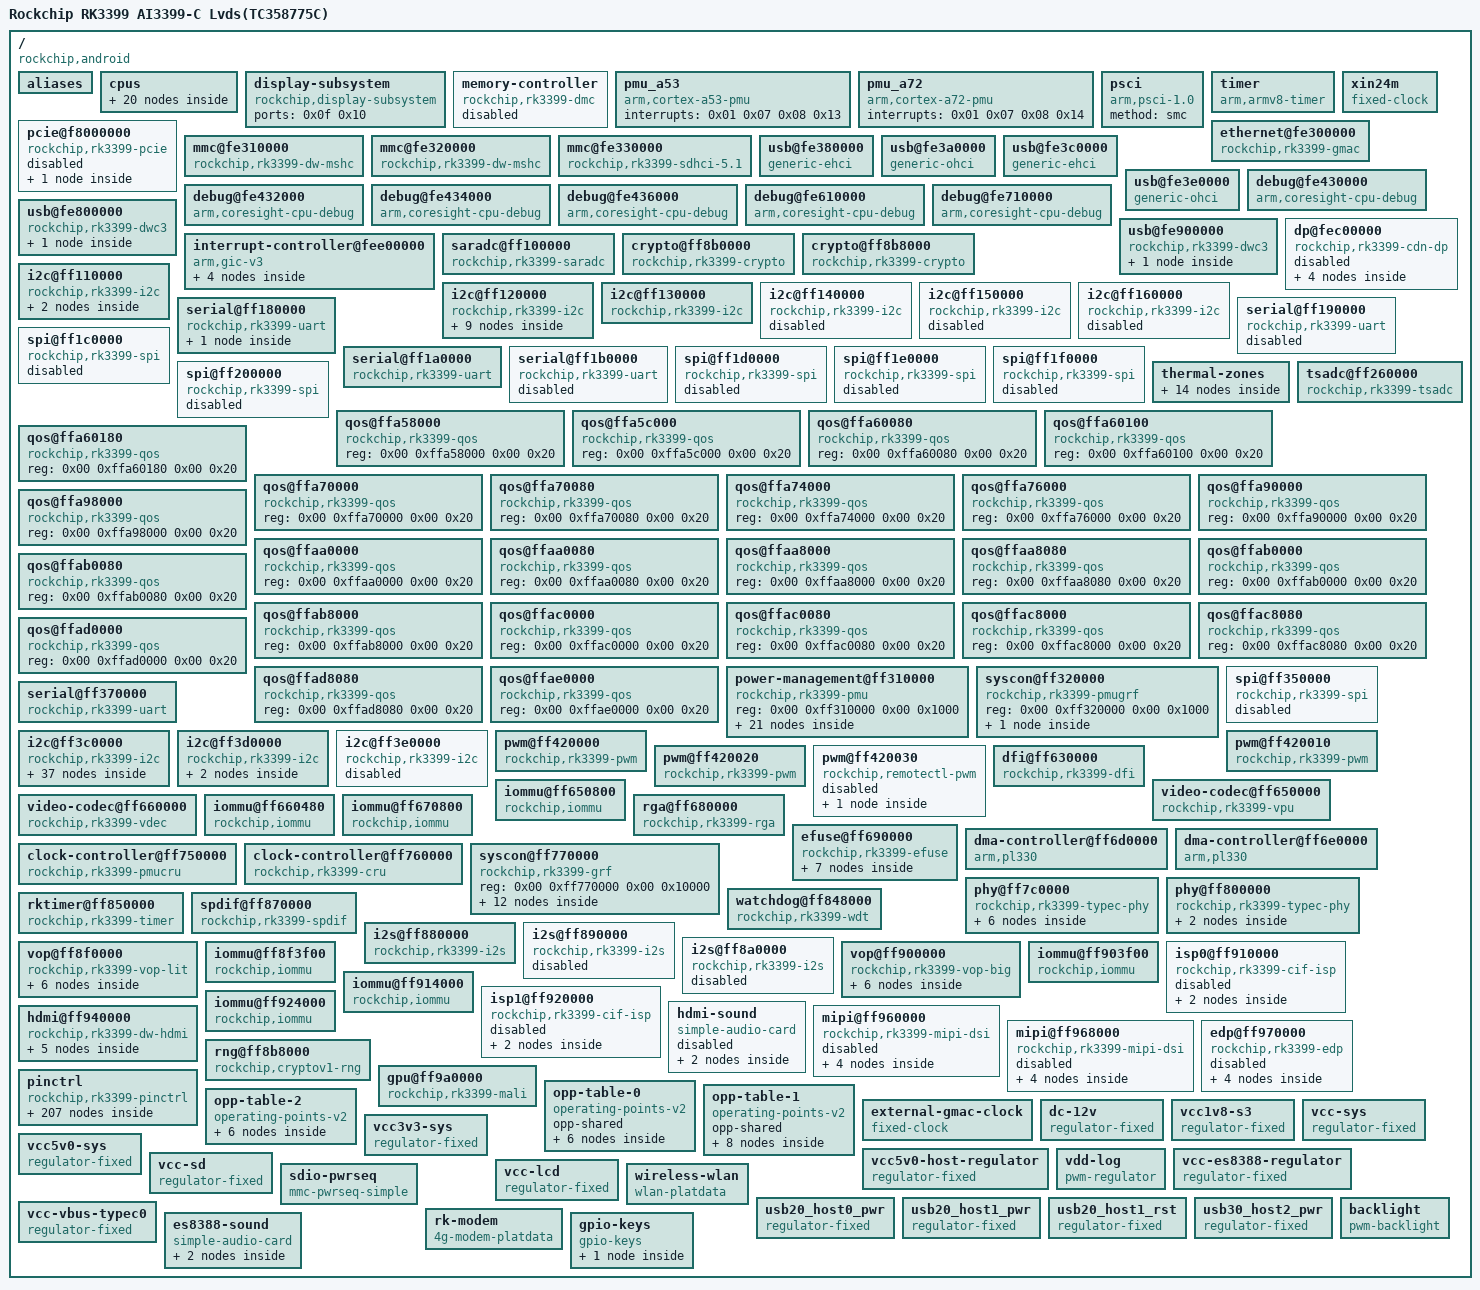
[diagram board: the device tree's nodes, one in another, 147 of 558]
/dts-v1/;

/ {
	compatible = "rockchip,android\0rockchip,rk3399-ai3399c-lvds\0rockchip,rk3399";
	interrupt-parent = <0x01>;
	#address-cells = <0x02>;
	#size-cells = <0x02>;
	serial-number = "STVQPGOW8K";
	model = "Rockchip RK3399 AI3399-C Lvds(TC358775C)";
	signway,hwid = "01.02.03.04.05.06.07.08";

	aliases {
		ethernet0 = "/ethernet@fe300000";
		i2c0 = "/i2c@ff3c0000";
		i2c1 = "/i2c@ff110000";
		i2c2 = "/i2c@ff120000";
		i2c3 = "/i2c@ff130000";
		i2c4 = "/i2c@ff3d0000";
		i2c5 = "/i2c@ff140000";
		i2c6 = "/i2c@ff150000";
		i2c7 = "/i2c@ff160000";
		i2c8 = "/i2c@ff3e0000";
		serial0 = "/serial@ff180000";
		serial1 = "/serial@ff190000";
		serial2 = "/serial@ff1a0000";
		serial3 = "/serial@ff1b0000";
		serial4 = "/serial@ff370000";
		mmc0 = "/mmc@fe330000";
	};

	cpus {
		#address-cells = <0x02>;
		#size-cells = <0x00>;

		cpu-map {

			cluster0 {

				core0 {
					cpu = <0x02>;
				};

				core1 {
					cpu = <0x03>;
				};

				core2 {
					cpu = <0x04>;
				};

				core3 {
					cpu = <0x05>;
				};
			};

			cluster1 {

				core0 {
					cpu = <0x06>;
				};

				core1 {
					cpu = <0x07>;
				};
			};
		};

		cpu@0 {
			device_type = "cpu";
			compatible = "arm,cortex-a53";
			reg = <0x00 0x00>;
			enable-method = "psci";
			capacity-dmips-mhz = <0x1e5>;
			clocks = <0x08 0x08>;
			#cooling-cells = <0x02>;
			dynamic-power-coefficient = <0x64>;
			cpu-idle-states = <0x09 0x0a>;
			operating-points-v2 = <0x0b>;
			cpu-supply = <0x0c>;
			phandle = <0x02>;
		};

		cpu@1 {
			device_type = "cpu";
			compatible = "arm,cortex-a53";
			reg = <0x00 0x01>;
			enable-method = "psci";
			capacity-dmips-mhz = <0x1e5>;
			clocks = <0x08 0x08>;
			#cooling-cells = <0x02>;
			dynamic-power-coefficient = <0x64>;
			cpu-idle-states = <0x09 0x0a>;
			operating-points-v2 = <0x0b>;
			cpu-supply = <0x0c>;
			phandle = <0x03>;
		};

		cpu@2 {
			device_type = "cpu";
			compatible = "arm,cortex-a53";
			reg = <0x00 0x02>;
			enable-method = "psci";
			capacity-dmips-mhz = <0x1e5>;
			clocks = <0x08 0x08>;
			#cooling-cells = <0x02>;
			dynamic-power-coefficient = <0x64>;
			cpu-idle-states = <0x09 0x0a>;
			operating-points-v2 = <0x0b>;
			cpu-supply = <0x0c>;
			phandle = <0x04>;
		};

		cpu@3 {
			device_type = "cpu";
			compatible = "arm,cortex-a53";
			reg = <0x00 0x03>;
			enable-method = "psci";
			capacity-dmips-mhz = <0x1e5>;
			clocks = <0x08 0x08>;
			#cooling-cells = <0x02>;
			dynamic-power-coefficient = <0x64>;
			cpu-idle-states = <0x09 0x0a>;
			operating-points-v2 = <0x0b>;
			cpu-supply = <0x0c>;
			phandle = <0x05>;
		};

		cpu@100 {
			device_type = "cpu";
			compatible = "arm,cortex-a72";
			reg = <0x00 0x100>;
			enable-method = "psci";
			capacity-dmips-mhz = <0x400>;
			clocks = <0x08 0x09>;
			#cooling-cells = <0x02>;
			dynamic-power-coefficient = <0x1b4>;
			cpu-idle-states = <0x09 0x0a>;
			operating-points-v2 = <0x0d>;
			cpu-supply = <0x0e>;
			phandle = <0x06>;

			thermal-idle {
				#cooling-cells = <0x02>;
				duration-us = <0x2710>;
				exit-latency-us = <0x1f4>;
			};
		};

		cpu@101 {
			device_type = "cpu";
			compatible = "arm,cortex-a72";
			reg = <0x00 0x101>;
			enable-method = "psci";
			capacity-dmips-mhz = <0x400>;
			clocks = <0x08 0x09>;
			#cooling-cells = <0x02>;
			dynamic-power-coefficient = <0x1b4>;
			cpu-idle-states = <0x09 0x0a>;
			operating-points-v2 = <0x0d>;
			cpu-supply = <0x0e>;
			phandle = <0x07>;

			thermal-idle {
				#cooling-cells = <0x02>;
				duration-us = <0x2710>;
				exit-latency-us = <0x1f4>;
			};
		};

		idle-states {
			entry-method = "psci";

			cpu-sleep {
				compatible = "arm,idle-state";
				local-timer-stop;
				arm,psci-suspend-param = <0x10000>;
				entry-latency-us = <0x78>;
				exit-latency-us = <0xfa>;
				min-residency-us = <0x384>;
				phandle = <0x09>;
			};

			cluster-sleep {
				compatible = "arm,idle-state";
				local-timer-stop;
				arm,psci-suspend-param = <0x1010000>;
				entry-latency-us = <0x190>;
				exit-latency-us = <0x1f4>;
				min-residency-us = <0x7d0>;
				phandle = <0x0a>;
			};
		};
	};

	display-subsystem {
		compatible = "rockchip,display-subsystem";
		ports = <0x0f 0x10>;
	};

	memory-controller {
		compatible = "rockchip,rk3399-dmc";
		rockchip,pmu = <0x11>;
		devfreq-events = <0x12>;
		clocks = <0x08 0xa8>;
		clock-names = "dmc_clk";
		status = "disabled";
		phandle = <0xdc>;
	};

	pmu_a53 {
		compatible = "arm,cortex-a53-pmu";
		interrupts = <0x01 0x07 0x08 0x13>;
	};

	pmu_a72 {
		compatible = "arm,cortex-a72-pmu";
		interrupts = <0x01 0x07 0x08 0x14>;
	};

	psci {
		compatible = "arm,psci-1.0";
		method = "smc";
	};

	timer {
		compatible = "arm,armv8-timer";
		interrupts = <0x01 0x0d 0x08 0x00 0x01 0x0e 0x08 0x00 0x01 0x0b 0x08 0x00 0x01 0x0a 0x08 0x00>;
		arm,no-tick-in-suspend;
	};

	xin24m {
		compatible = "fixed-clock";
		clock-frequency = <0x16e3600>;
		clock-output-names = "xin24m";
		#clock-cells = <0x00>;
		phandle = <0x9b>;
	};

	pcie@f8000000 {
		compatible = "rockchip,rk3399-pcie";
		reg = <0x00 0xf8000000 0x00 0x2000000 0x00 0xfd000000 0x00 0x1000000>;
		reg-names = "axi-base\0apb-base";
		device_type = "pci";
		#address-cells = <0x03>;
		#size-cells = <0x02>;
		#interrupt-cells = <0x01>;
		aspm-no-l0s;
		bus-range = <0x00 0x1f>;
		clocks = <0x08 0xc5 0x08 0xc4 0x08 0x147 0x08 0xa0>;
		clock-names = "aclk\0aclk-perf\0hclk\0pm";
		interrupts = <0x00 0x31 0x04 0x00 0x00 0x32 0x04 0x00 0x00 0x33 0x04 0x00>;
		interrupt-names = "sys\0legacy\0client";
		interrupt-map-mask = <0x00 0x00 0x00 0x07>;
		interrupt-map = <0x00 0x00 0x00 0x01 0x15 0x00 0x00 0x00 0x00 0x02 0x15 0x01 0x00 0x00 0x00 0x03 0x15 0x02 0x00 0x00 0x00 0x04 0x15 0x03>;
		max-link-speed = <0x01>;
		msi-map = <0x00 0x16 0x00 0x1000>;
		phys = <0x17 0x00 0x17 0x01 0x17 0x02 0x17 0x03>;
		phy-names = "pcie-phy-0\0pcie-phy-1\0pcie-phy-2\0pcie-phy-3";
		ranges = <0x82000000 0x00 0xfa000000 0x00 0xfa000000 0x00 0x1e00000 0x81000000 0x00 0xfbe00000 0x00 0xfbe00000 0x00 0x100000>;
		resets = <0x08 0x82 0x08 0x83 0x08 0x84 0x08 0x85 0x08 0x86 0x08 0x81 0x08 0x80>;
		reset-names = "core\0mgmt\0mgmt-sticky\0pipe\0pm\0pclk\0aclk";
		status = "disabled";
		phandle = <0xdd>;

		interrupt-controller {
			interrupt-controller;
			#address-cells = <0x00>;
			#interrupt-cells = <0x01>;
			phandle = <0x15>;
		};
	};

	ethernet@fe300000 {
		compatible = "rockchip,rk3399-gmac";
		reg = <0x00 0xfe300000 0x00 0x10000>;
		interrupts = <0x00 0x0c 0x04 0x00>;
		interrupt-names = "macirq";
		clocks = <0x08 0x69 0x08 0x67 0x08 0x68 0x08 0x66 0x08 0x6a 0x08 0xd5 0x08 0x166>;
		clock-names = "stmmaceth\0mac_clk_rx\0mac_clk_tx\0clk_mac_ref\0clk_mac_refout\0aclk_mac\0pclk_mac";
		power-domains = <0x18 0x16>;
		resets = <0x08 0x89>;
		reset-names = "stmmaceth";
		rockchip,grf = <0x19>;
		snps,txpbl = <0x04>;
		status = "okay";
		phy-supply = <0x1a>;
		phy-mode = "rgmii";
		clock_in_out = "input";
		snps,reset-gpio = <0x1b 0x0f 0x01>;
		snps,reset-active-low;
		snps,reset-delays-us = <0x00 0x2710 0xc350>;
		assigned-clocks = <0x08 0xa6>;
		assigned-clock-parents = <0x1c>;
		pinctrl-names = "default";
		pinctrl-0 = <0x1d>;
		tx_delay = <0x34>;
		rx_delay = <0x27>;
		phandle = <0xde>;
	};

	mmc@fe310000 {
		compatible = "rockchip,rk3399-dw-mshc\0rockchip,rk3288-dw-mshc";
		reg = <0x00 0xfe310000 0x00 0x4000>;
		interrupts = <0x00 0x40 0x04 0x00>;
		max-frequency = <0x8f0d180>;
		clocks = <0x08 0x1ee 0x08 0x4d 0x08 0x9c 0x08 0x9d>;
		clock-names = "biu\0ciu\0ciu-drive\0ciu-sample";
		fifo-depth = <0x100>;
		power-domains = <0x18 0x1c>;
		resets = <0x08 0x79>;
		reset-names = "reset";
		status = "okay";
		bus-width = <0x04>;
		cap-sdio-irq;
		cap-sd-highspeed;
		keep-power-in-suspend;
		mmc-pwrseq = <0x1e>;
		non-removable;
		pinctrl-names = "default";
		pinctrl-0 = <0x1f 0x20 0x21>;
		sd-uhs-sdr104;
		#address-cells = <0x01>;
		#size-cells = <0x00>;
		phandle = <0xdf>;
	};

	mmc@fe320000 {
		compatible = "rockchip,rk3399-dw-mshc\0rockchip,rk3288-dw-mshc";
		reg = <0x00 0xfe320000 0x00 0x4000>;
		interrupts = <0x00 0x41 0x04 0x00>;
		max-frequency = <0x8f0d180>;
		assigned-clocks = <0x08 0x1cd>;
		assigned-clock-rates = <0xbebc200>;
		clocks = <0x08 0x1ce 0x08 0x4c 0x08 0x9a 0x08 0x9b>;
		clock-names = "biu\0ciu\0ciu-drive\0ciu-sample";
		fifo-depth = <0x100>;
		power-domains = <0x18 0x1b>;
		resets = <0x08 0x7a>;
		reset-names = "reset";
		status = "okay";
		bus-width = <0x04>;
		cap-mmc-highspeed;
		cap-sd-highspeed;
		supports-sd;
		clock-frequency = <0x8f0d180>;
		cd-gpios = <0x22 0x07 0x01>;
		disable-wp;
		sd-uhs-sdr104;
		pinctrl-names = "default";
		pinctrl-0 = <0x23 0x24 0x25 0x26>;
		vqmmc-supply = <0x27>;
		vmmc-supply = <0x28>;
		phandle = <0xe0>;
	};

	mmc@fe330000 {
		compatible = "rockchip,rk3399-sdhci-5.1\0arasan,sdhci-5.1";
		reg = <0x00 0xfe330000 0x00 0x10000>;
		interrupts = <0x00 0x0b 0x04 0x00>;
		arasan,soc-ctl-syscon = <0x19>;
		assigned-clocks = <0x08 0x4e>;
		assigned-clock-rates = <0xbebc200>;
		clocks = <0x08 0x4e 0x08 0xf0>;
		clock-names = "clk_xin\0clk_ahb";
		clock-output-names = "emmc_cardclock";
		#clock-cells = <0x00>;
		phys = <0x29>;
		phy-names = "phy_arasan";
		power-domains = <0x18 0x17>;
		disable-cqe-dcmd;
		status = "okay";
		bus-width = <0x08>;
		mmc-hs400-1_8v;
		mmc-hs400-enhanced-strobe;
		keep-power-in-suspend;
		non-removable;
		supports-emmc;
		phandle = <0x9e>;
	};

	usb@fe380000 {
		compatible = "generic-ehci";
		reg = <0x00 0xfe380000 0x00 0x20000>;
		interrupts = <0x00 0x1a 0x04 0x00>;
		clocks = <0x08 0x1c8 0x08 0x1c9 0x2a>;
		phys = <0x2b>;
		phy-names = "usb";
		status = "okay";
		phandle = <0xe1>;
	};

	usb@fe3a0000 {
		compatible = "generic-ohci";
		reg = <0x00 0xfe3a0000 0x00 0x20000>;
		interrupts = <0x00 0x1c 0x04 0x00>;
		clocks = <0x08 0x1c8 0x08 0x1c9 0x2a>;
		phys = <0x2b>;
		phy-names = "usb";
		status = "okay";
		phandle = <0xe2>;
	};

	usb@fe3c0000 {
		compatible = "generic-ehci";
		reg = <0x00 0xfe3c0000 0x00 0x20000>;
		interrupts = <0x00 0x1e 0x04 0x00>;
		clocks = <0x08 0x1ca 0x08 0x1cb 0x2c>;
		phys = <0x2d>;
		phy-names = "usb";
		status = "okay";
		phandle = <0xe3>;
	};

	usb@fe3e0000 {
		compatible = "generic-ohci";
		reg = <0x00 0xfe3e0000 0x00 0x20000>;
		interrupts = <0x00 0x20 0x04 0x00>;
		clocks = <0x08 0x1ca 0x08 0x1cb 0x2c>;
		phys = <0x2d>;
		phy-names = "usb";
		status = "okay";
		phandle = <0xe4>;
	};

	debug@fe430000 {
		compatible = "arm,coresight-cpu-debug\0arm,primecell";
		reg = <0x00 0xfe430000 0x00 0x1000>;
		clocks = <0x08 0x14d>;
		clock-names = "apb_pclk";
		cpu = <0x02>;
	};

	debug@fe432000 {
		compatible = "arm,coresight-cpu-debug\0arm,primecell";
		reg = <0x00 0xfe432000 0x00 0x1000>;
		clocks = <0x08 0x14d>;
		clock-names = "apb_pclk";
		cpu = <0x03>;
	};

	debug@fe434000 {
		compatible = "arm,coresight-cpu-debug\0arm,primecell";
		reg = <0x00 0xfe434000 0x00 0x1000>;
		clocks = <0x08 0x14d>;
		clock-names = "apb_pclk";
		cpu = <0x04>;
	};

	debug@fe436000 {
		compatible = "arm,coresight-cpu-debug\0arm,primecell";
		reg = <0x00 0xfe436000 0x00 0x1000>;
		clocks = <0x08 0x14d>;
		clock-names = "apb_pclk";
		cpu = <0x05>;
	};

	debug@fe610000 {
		compatible = "arm,coresight-cpu-debug\0arm,primecell";
		reg = <0x00 0xfe610000 0x00 0x1000>;
		clocks = <0x08 0x14c>;
		clock-names = "apb_pclk";
		cpu = <0x06>;
	};

	debug@fe710000 {
		compatible = "arm,coresight-cpu-debug\0arm,primecell";
		reg = <0x00 0xfe710000 0x00 0x1000>;
		clocks = <0x08 0x14c>;
		clock-names = "apb_pclk";
		cpu = <0x07>;
	};

	usb@fe800000 {
		compatible = "rockchip,rk3399-dwc3";
		#address-cells = <0x02>;
		#size-cells = <0x02>;
		ranges;
		clocks = <0x08 0x81 0x08 0x83 0x08 0xf6 0x08 0xf8 0x08 0xf4 0x08 0xf9>;
		clock-names = "ref_clk\0suspend_clk\0bus_clk\0aclk_usb3_rksoc_axi_perf\0aclk_usb3\0grf_clk";
		resets = <0x08 0x125>;
		reset-names = "usb3-otg";
		status = "okay";
		phandle = <0xe5>;

		usb@fe800000 {
			compatible = "snps,dwc3";
			reg = <0x00 0xfe800000 0x00 0x100000>;
			interrupts = <0x00 0x69 0x04 0x00>;
			clocks = <0x08 0x81 0x08 0xf6 0x08 0x83>;
			clock-names = "ref\0bus_early\0suspend";
			dr_mode = "host";
			phys = <0x2e 0x2f>;
			phy-names = "usb2-phy\0usb3-phy";
			phy_type = "utmi_wide";
			snps,dis_enblslpm_quirk;
			snps,dis-u2-freeclk-exists-quirk;
			snps,dis_u2_susphy_quirk;
			snps,dis-del-phy-power-chg-quirk;
			snps,dis-tx-ipgap-linecheck-quirk;
			power-domains = <0x18 0x18>;
			status = "okay";
			phandle = <0xe6>;
		};
	};

	usb@fe900000 {
		compatible = "rockchip,rk3399-dwc3";
		#address-cells = <0x02>;
		#size-cells = <0x02>;
		ranges;
		clocks = <0x08 0x82 0x08 0x84 0x08 0xf7 0x08 0xf8 0x08 0xf4 0x08 0xf9>;
		clock-names = "ref_clk\0suspend_clk\0bus_clk\0aclk_usb3_rksoc_axi_perf\0aclk_usb3\0grf_clk";
		resets = <0x08 0x126>;
		reset-names = "usb3-otg";
		status = "okay";
		phandle = <0xe7>;

		usb@fe900000 {
			compatible = "snps,dwc3";
			reg = <0x00 0xfe900000 0x00 0x100000>;
			interrupts = <0x00 0x6e 0x04 0x00>;
			clocks = <0x08 0x82 0x08 0xf7 0x08 0x84>;
			clock-names = "ref\0bus_early\0suspend";
			dr_mode = "host";
			phys = <0x30 0x31>;
			phy-names = "usb2-phy\0usb3-phy";
			phy_type = "utmi_wide";
			snps,dis_enblslpm_quirk;
			snps,dis-u2-freeclk-exists-quirk;
			snps,dis_u2_susphy_quirk;
			snps,dis-del-phy-power-chg-quirk;
			snps,dis-tx-ipgap-linecheck-quirk;
			power-domains = <0x18 0x18>;
			status = "okay";
			phandle = <0xe8>;
		};
	};

	dp@fec00000 {
		compatible = "rockchip,rk3399-cdn-dp";
		reg = <0x00 0xfec00000 0x00 0x100000>;
		interrupts = <0x00 0x09 0x04 0x00>;
		assigned-clocks = <0x08 0x72 0x08 0xa1>;
		assigned-clock-rates = <0x5f5e100 0xbebc200>;
		clocks = <0x08 0x72 0x08 0x175 0x08 0xa1 0x08 0x16f>;
		clock-names = "core-clk\0pclk\0spdif\0grf";
		phys = <0x32 0x33>;
		power-domains = <0x18 0x15>;
		resets = <0x08 0x103 0x08 0x148 0x08 0x14a 0x08 0xfd>;
		reset-names = "spdif\0dptx\0apb\0core";
		rockchip,grf = <0x19>;
		#sound-dai-cells = <0x01>;
		status = "disabled";
		phandle = <0xe9>;

		ports {

			port {
				#address-cells = <0x01>;
				#size-cells = <0x00>;
				phandle = <0xea>;

				endpoint@0 {
					reg = <0x00>;
					remote-endpoint = <0x34>;
					phandle = <0xb1>;
				};

				endpoint@1 {
					reg = <0x01>;
					remote-endpoint = <0x35>;
					phandle = <0xab>;
				};
			};
		};
	};

	interrupt-controller@fee00000 {
		compatible = "arm,gic-v3";
		#interrupt-cells = <0x04>;
		#address-cells = <0x02>;
		#size-cells = <0x02>;
		ranges;
		interrupt-controller;
		reg = <0x00 0xfee00000 0x00 0x10000 0x00 0xfef00000 0x00 0xc0000 0x00 0xfff00000 0x00 0x10000 0x00 0xfff10000 0x00 0x10000 0x00 0xfff20000 0x00 0x10000>;
		interrupts = <0x01 0x09 0x04 0x00>;
		phandle = <0x01>;

		interrupt-controller@fee20000 {
			compatible = "arm,gic-v3-its";
			msi-controller;
			#msi-cells = <0x01>;
			reg = <0x00 0xfee20000 0x00 0x20000>;
			phandle = <0x16>;
		};

		ppi-partitions {

			interrupt-partition-0 {
				affinity = <0x02 0x03 0x04 0x05>;
				phandle = <0x13>;
			};

			interrupt-partition-1 {
				affinity = <0x06 0x07>;
				phandle = <0x14>;
			};
		};
	};

	saradc@ff100000 {
		compatible = "rockchip,rk3399-saradc";
		reg = <0x00 0xff100000 0x00 0x100>;
		interrupts = <0x00 0x3e 0x04 0x00>;
		#io-channel-cells = <0x01>;
		clocks = <0x08 0x50 0x08 0x165>;
		clock-names = "saradc\0apb_pclk";
		resets = <0x08 0xd4>;
		reset-names = "saradc-apb";
		status = "okay";
		vref-supply = <0x36>;
		phandle = <0xeb>;
	};

	crypto@ff8b0000 {
		compatible = "rockchip,rk3399-crypto";
		reg = <0x00 0xff8b0000 0x00 0x4000>;
		interrupts = <0x00 0x00 0x04 0x00>;
		clocks = <0x08 0x1d0 0x08 0x1d2 0x08 0x85>;
		clock-names = "hclk_master\0hclk_slave\0sclk";
		resets = <0x08 0xb5 0x08 0xae 0x08 0xaf>;
		reset-names = "master\0lave\0crypto";
		phandle = <0xec>;
	};

	crypto@ff8b8000 {
		compatible = "rockchip,rk3399-crypto";
		reg = <0x00 0xff8b8000 0x00 0x4000>;
		interrupts = <0x00 0x87 0x04 0x00>;
		clocks = <0x08 0x1d1 0x08 0x1d3 0x08 0x86>;
		clock-names = "hclk_master\0hclk_slave\0sclk";
		resets = <0x08 0xba 0x08 0xb8 0x08 0xb9>;
		reset-names = "master\0slave\0crypto";
		phandle = <0xed>;
	};

	i2c@ff110000 {
		compatible = "rockchip,rk3399-i2c";
		reg = <0x00 0xff110000 0x00 0x1000>;
		assigned-clocks = <0x08 0x41>;
		assigned-clock-rates = <0xbebc200>;
		clocks = <0x08 0x41 0x08 0x155>;
		clock-names = "i2c\0pclk";
		interrupts = <0x00 0x3b 0x04 0x00>;
		pinctrl-names = "default";
		pinctrl-0 = <0x37>;
		#address-cells = <0x01>;
		#size-cells = <0x00>;
		status = "okay";
		phandle = <0xee>;

		es8388@11 {
			status = "okay";
			compatible = "everest,es8388";
			reg = <0x11>;
			clocks = <0x08 0x59>;
			clock-names = "mclk";
			#sound-dai-cells = <0x00>;
			amp-gain-gpios = <0x38 0x12 0x00>;
			spk-ctl-gpios = <0x38 0x18 0x00>;
			pinctrl-names = "default";
			pinctrl-0 = <0x39 0x3a>;
			AVDD-supply = <0x3b>;
			DVDD-supply = <0x3b>;
			HPVDD-supply = <0x3b>;
			PVDD-supply = <0x3b>;
			phandle = <0xd9>;
		};

		sw201@50 {
			status = "okay";
			compatible = "eeprom,sw201";
			reg = <0x50>;
			phandle = <0xef>;
		};
	};

	i2c@ff120000 {
		compatible = "rockchip,rk3399-i2c";
		reg = <0x00 0xff120000 0x00 0x1000>;
		assigned-clocks = <0x08 0x42>;
		assigned-clock-rates = <0xbebc200>;
		clocks = <0x08 0x42 0x08 0x156>;
		clock-names = "i2c\0pclk";
		interrupts = <0x00 0x23 0x04 0x00>;
		pinctrl-names = "default";
		pinctrl-0 = <0x3c>;
		#address-cells = <0x01>;
		#size-cells = <0x00>;
		status = "okay";
		phandle = <0xf0>;

		fusb30x@22 {
			compatible = "fcs,fusb302";
			reg = <0x22>;
			pinctrl-names = "default";
			pinctrl-0 = <0x3d>;
			interrupt-parent = <0x3e>;
			interrupts = <0x05 0x08>;
			vbus-supply = <0x3f>;
			status = "okay";
			phandle = <0xf1>;

			connector {
				compatible = "usb-c-connector";
				data-role = "dual";
				label = "USB-C";
				op-sink-microwatt = <0xf4240>;
				power-role = "dual";
				sink-pdos = <0x40190fa>;
				source-pdos = <0x401908c>;
				try-power-role = "sink";
				phandle = <0xf2>;

				ports {
					#address-cells = <0x01>;
					#size-cells = <0x00>;

					port@0 {
						reg = <0x00>;

						endpoint {
							remote-endpoint = <0x40>;
							phandle = <0x9d>;
						};
					};

					port@1 {
						reg = <0x01>;

						endpoint {
							remote-endpoint = <0x41>;
							phandle = <0xa0>;
						};
					};

					port@2 {
						reg = <0x02>;

						endpoint {
							remote-endpoint = <0x42>;
							phandle = <0x9f>;
						};
					};
				};
			};
		};
	};

	i2c@ff130000 {
		compatible = "rockchip,rk3399-i2c";
		reg = <0x00 0xff130000 0x00 0x1000>;
		assigned-clocks = <0x08 0x43>;
		assigned-clock-rates = <0xbebc200>;
		clocks = <0x08 0x43 0x08 0x157>;
		clock-names = "i2c\0pclk";
		interrupts = <0x00 0x22 0x04 0x00>;
		pinctrl-names = "default";
		pinctrl-0 = <0x43>;
		#address-cells = <0x01>;
		#size-cells = <0x00>;
		status = "okay";
		i2c-scl-rising-time-ns = <0x1c2>;
		i2c-scl-falling-time-ns = <0x0f>;
		phandle = <0xba>;
	};

	i2c@ff140000 {
		compatible = "rockchip,rk3399-i2c";
		reg = <0x00 0xff140000 0x00 0x1000>;
		assigned-clocks = <0x08 0x44>;
		assigned-clock-rates = <0xbebc200>;
		clocks = <0x08 0x44 0x08 0x158>;
		clock-names = "i2c\0pclk";
		interrupts = <0x00 0x26 0x04 0x00>;
		pinctrl-names = "default";
		pinctrl-0 = <0x44>;
		#address-cells = <0x01>;
		#size-cells = <0x00>;
		status = "disabled";
		phandle = <0xf3>;
	};

	i2c@ff150000 {
		compatible = "rockchip,rk3399-i2c";
		reg = <0x00 0xff150000 0x00 0x1000>;
		assigned-clocks = <0x08 0x45>;
		assigned-clock-rates = <0xbebc200>;
		clocks = <0x08 0x45 0x08 0x159>;
		clock-names = "i2c\0pclk";
		interrupts = <0x00 0x25 0x04 0x00>;
		pinctrl-names = "default";
		pinctrl-0 = <0x45>;
		#address-cells = <0x01>;
		#size-cells = <0x00>;
		status = "disabled";
		phandle = <0xf4>;
	};

	i2c@ff160000 {
		compatible = "rockchip,rk3399-i2c";
		reg = <0x00 0xff160000 0x00 0x1000>;
		assigned-clocks = <0x08 0x46>;
		assigned-clock-rates = <0xbebc200>;
		clocks = <0x08 0x46 0x08 0x15a>;
		clock-names = "i2c\0pclk";
		interrupts = <0x00 0x24 0x04 0x00>;
		pinctrl-names = "default";
		pinctrl-0 = <0x46>;
		#address-cells = <0x01>;
		#size-cells = <0x00>;
		status = "disabled";
		phandle = <0xf5>;
	};

	serial@ff180000 {
		compatible = "rockchip,rk3399-uart\0snps,dw-apb-uart";
		reg = <0x00 0xff180000 0x00 0x100>;
		clocks = <0x08 0x51 0x08 0x160>;
		clock-names = "baudclk\0apb_pclk";
		interrupts = <0x00 0x63 0x04 0x00>;
		reg-shift = <0x02>;
		reg-io-width = <0x04>;
		pinctrl-names = "default";
		pinctrl-0 = <0x47 0x48 0x49>;
		status = "okay";
		phandle = <0xf6>;

		bluetooth {
			compatible = "brcm,bcm43438-bt";
			clocks = <0x4a 0x01>;
			clock-names = "extclk";
			host-wakeup-gpios = <0x22 0x04 0x00>;
			device-wakeup-gpios = <0x3e 0x1b 0x00>;
			shutdown-gpios = <0x22 0x09 0x00>;
			pinctrl-names = "default";
			pinctrl-0 = <0x4b 0x4c 0x4d>;
			vbat-supply = <0x4e>;
			vddio-supply = <0x36>;
		};
	};

	serial@ff190000 {
		compatible = "rockchip,rk3399-uart\0snps,dw-apb-uart";
		reg = <0x00 0xff190000 0x00 0x100>;
		clocks = <0x08 0x52 0x08 0x161>;
		clock-names = "baudclk\0apb_pclk";
		interrupts = <0x00 0x62 0x04 0x00>;
		reg-shift = <0x02>;
		reg-io-width = <0x04>;
		pinctrl-names = "default";
		pinctrl-0 = <0x4f>;
		status = "disabled";
		phandle = <0xf7>;
	};

	serial@ff1a0000 {
		compatible = "rockchip,rk3399-uart\0snps,dw-apb-uart";
		reg = <0x00 0xff1a0000 0x00 0x100>;
		clocks = <0x08 0x53 0x08 0x162>;
		clock-names = "baudclk\0apb_pclk";
		interrupts = <0x00 0x64 0x04 0x00>;
		reg-shift = <0x02>;
		reg-io-width = <0x04>;
		pinctrl-names = "default";
		pinctrl-0 = <0x50>;
		status = "okay";
		phandle = <0xf8>;
	};

	serial@ff1b0000 {
		compatible = "rockchip,rk3399-uart\0snps,dw-apb-uart";
		reg = <0x00 0xff1b0000 0x00 0x100>;
		clocks = <0x08 0x54 0x08 0x163>;
		clock-names = "baudclk\0apb_pclk";
		interrupts = <0x00 0x65 0x04 0x00>;
		reg-shift = <0x02>;
		reg-io-width = <0x04>;
		pinctrl-names = "default";
		pinctrl-0 = <0x51>;
		status = "disabled";
		phandle = <0xf9>;
	};

	spi@ff1c0000 {
		compatible = "rockchip,rk3399-spi\0rockchip,rk3066-spi";
		reg = <0x00 0xff1c0000 0x00 0x1000>;
		clocks = <0x08 0x47 0x08 0x15b>;
		clock-names = "spiclk\0apb_pclk";
		interrupts = <0x00 0x44 0x04 0x00>;
		dmas = <0x52 0x0a 0x52 0x0b>;
		dma-names = "tx\0rx";
		pinctrl-names = "default";
		pinctrl-0 = <0x53 0x54 0x55 0x56>;
		#address-cells = <0x01>;
		#size-cells = <0x00>;
		status = "disabled";
		phandle = <0xfa>;
	};

	spi@ff1d0000 {
		compatible = "rockchip,rk3399-spi\0rockchip,rk3066-spi";
		reg = <0x00 0xff1d0000 0x00 0x1000>;
		clocks = <0x08 0x48 0x08 0x15c>;
		clock-names = "spiclk\0apb_pclk";
		interrupts = <0x00 0x35 0x04 0x00>;
		dmas = <0x52 0x0c 0x52 0x0d>;
		dma-names = "tx\0rx";
		pinctrl-names = "default";
		pinctrl-0 = <0x57 0x58 0x59 0x5a>;
		#address-cells = <0x01>;
		#size-cells = <0x00>;
		status = "disabled";
		phandle = <0xfb>;
	};

	spi@ff1e0000 {
		compatible = "rockchip,rk3399-spi\0rockchip,rk3066-spi";
		reg = <0x00 0xff1e0000 0x00 0x1000>;
		clocks = <0x08 0x49 0x08 0x15d>;
		clock-names = "spiclk\0apb_pclk";
		interrupts = <0x00 0x34 0x04 0x00>;
		dmas = <0x52 0x0e 0x52 0x0f>;
		dma-names = "tx\0rx";
		pinctrl-names = "default";
		pinctrl-0 = <0x5b 0x5c 0x5d 0x5e>;
		#address-cells = <0x01>;
		#size-cells = <0x00>;
		status = "disabled";
		phandle = <0xfc>;
	};

	spi@ff1f0000 {
		compatible = "rockchip,rk3399-spi\0rockchip,rk3066-spi";
		reg = <0x00 0xff1f0000 0x00 0x1000>;
		clocks = <0x08 0x4a 0x08 0x15e>;
		clock-names = "spiclk\0apb_pclk";
		interrupts = <0x00 0x43 0x04 0x00>;
		dmas = <0x52 0x12 0x52 0x13>;
		dma-names = "tx\0rx";
		pinctrl-names = "default";
		pinctrl-0 = <0x5f 0x60 0x61 0x62>;
		#address-cells = <0x01>;
		#size-cells = <0x00>;
		status = "disabled";
		phandle = <0xfd>;
	};

	spi@ff200000 {
		compatible = "rockchip,rk3399-spi\0rockchip,rk3066-spi";
		reg = <0x00 0xff200000 0x00 0x1000>;
		clocks = <0x08 0x4b 0x08 0x15f>;
		clock-names = "spiclk\0apb_pclk";
		interrupts = <0x00 0x84 0x04 0x00>;
		dmas = <0x63 0x08 0x63 0x09>;
		dma-names = "tx\0rx";
		pinctrl-names = "default";
		pinctrl-0 = <0x64 0x65 0x66 0x67>;
		power-domains = <0x18 0x1c>;
		#address-cells = <0x01>;
		#size-cells = <0x00>;
		status = "disabled";
		phandle = <0xfe>;
	};

	thermal-zones {
		phandle = <0xff>;

		cpu-thermal {
			polling-delay-passive = <0x64>;
			polling-delay = <0x3e8>;
			thermal-sensors = <0x68 0x00>;
			phandle = <0x100>;

			trips {

				cpu_alert0 {
					temperature = <0x11170>;
					hysteresis = <0x7d0>;
					type = "passive";
					phandle = <0x69>;
				};

				cpu_alert1 {
					temperature = <0x124f8>;
					hysteresis = <0x7d0>;
					type = "passive";
					phandle = <0x6a>;
				};

				cpu_crit {
					temperature = <0x17318>;
					hysteresis = <0x7d0>;
					type = "critical";
					phandle = <0x101>;
				};
			};

			cooling-maps {

				map0 {
					trip = <0x69>;
					cooling-device = <0x06 0xffffffff 0xffffffff 0x07 0xffffffff 0xffffffff>;
				};

				map1 {
					trip = <0x6a>;
					cooling-device = <0x02 0xffffffff 0xffffffff 0x03 0xffffffff 0xffffffff 0x04 0xffffffff 0xffffffff 0x05 0xffffffff 0xffffffff 0x06 0xffffffff 0xffffffff 0x07 0xffffffff 0xffffffff>;
				};
			};
		};

		gpu-thermal {
			polling-delay-passive = <0x64>;
			polling-delay = <0x3e8>;
			thermal-sensors = <0x68 0x01>;
			phandle = <0x102>;

			trips {

				gpu_alert0 {
					temperature = <0x124f8>;
					hysteresis = <0x7d0>;
					type = "passive";
					phandle = <0x6b>;
				};

				gpu_crit {
					temperature = <0x17318>;
					hysteresis = <0x7d0>;
					type = "critical";
					phandle = <0x103>;
				};
			};

			cooling-maps {

				map0 {
					trip = <0x6b>;
					cooling-device = <0x6c 0xffffffff 0xffffffff>;
				};
			};
		};
	};

	tsadc@ff260000 {
		compatible = "rockchip,rk3399-tsadc";
		reg = <0x00 0xff260000 0x00 0x100>;
		interrupts = <0x00 0x61 0x04 0x00>;
		assigned-clocks = <0x08 0x4f>;
		assigned-clock-rates = <0xb71b0>;
		clocks = <0x08 0x4f 0x08 0x164>;
		clock-names = "tsadc\0apb_pclk";
		resets = <0x08 0xe8>;
		reset-names = "tsadc-apb";
		rockchip,grf = <0x19>;
		rockchip,hw-tshut-temp = <0x1d4c0>;
		pinctrl-names = "init\0default\0sleep";
		pinctrl-0 = <0x6d>;
		pinctrl-1 = <0x6e>;
		pinctrl-2 = <0x6d>;
		#thermal-sensor-cells = <0x01>;
		status = "okay";
		rockchip,hw-tshut-mode = <0x01>;
		rockchip,hw-tshut-polarity = <0x01>;
		phandle = <0x68>;
	};

	qos@ffa58000 {
		compatible = "rockchip,rk3399-qos\0syscon";
		reg = <0x00 0xffa58000 0x00 0x20>;
		phandle = <0x76>;
	};

	qos@ffa5c000 {
		compatible = "rockchip,rk3399-qos\0syscon";
		reg = <0x00 0xffa5c000 0x00 0x20>;
		phandle = <0x77>;
	};

	qos@ffa60080 {
		compatible = "rockchip,rk3399-qos\0syscon";
		reg = <0x00 0xffa60080 0x00 0x20>;
		phandle = <0x104>;
	};

	qos@ffa60100 {
		compatible = "rockchip,rk3399-qos\0syscon";
		reg = <0x00 0xffa60100 0x00 0x20>;
		phandle = <0x105>;
	};

	qos@ffa60180 {
		compatible = "rockchip,rk3399-qos\0syscon";
		reg = <0x00 0xffa60180 0x00 0x20>;
		phandle = <0x106>;
	};

	qos@ffa70000 {
		compatible = "rockchip,rk3399-qos\0syscon";
		reg = <0x00 0xffa70000 0x00 0x20>;
		phandle = <0x7a>;
	};

	qos@ffa70080 {
		compatible = "rockchip,rk3399-qos\0syscon";
		reg = <0x00 0xffa70080 0x00 0x20>;
		phandle = <0x7b>;
	};

	qos@ffa74000 {
		compatible = "rockchip,rk3399-qos\0syscon";
		reg = <0x00 0xffa74000 0x00 0x20>;
		phandle = <0x78>;
	};

	qos@ffa76000 {
		compatible = "rockchip,rk3399-qos\0syscon";
		reg = <0x00 0xffa76000 0x00 0x20>;
		phandle = <0x79>;
	};

	qos@ffa90000 {
		compatible = "rockchip,rk3399-qos\0syscon";
		reg = <0x00 0xffa90000 0x00 0x20>;
		phandle = <0x7c>;
	};

	qos@ffa98000 {
		compatible = "rockchip,rk3399-qos\0syscon";
		reg = <0x00 0xffa98000 0x00 0x20>;
		phandle = <0x6f>;
	};

	qos@ffaa0000 {
		compatible = "rockchip,rk3399-qos\0syscon";
		reg = <0x00 0xffaa0000 0x00 0x20>;
		phandle = <0x7d>;
	};

	qos@ffaa0080 {
		compatible = "rockchip,rk3399-qos\0syscon";
		reg = <0x00 0xffaa0080 0x00 0x20>;
		phandle = <0x7e>;
	};

	qos@ffaa8000 {
		compatible = "rockchip,rk3399-qos\0syscon";
		reg = <0x00 0xffaa8000 0x00 0x20>;
		phandle = <0x7f>;
	};

	qos@ffaa8080 {
		compatible = "rockchip,rk3399-qos\0syscon";
		reg = <0x00 0xffaa8080 0x00 0x20>;
		phandle = <0x80>;
	};

	qos@ffab0000 {
		compatible = "rockchip,rk3399-qos\0syscon";
		reg = <0x00 0xffab0000 0x00 0x20>;
		phandle = <0x70>;
	};

	qos@ffab0080 {
		compatible = "rockchip,rk3399-qos\0syscon";
		reg = <0x00 0xffab0080 0x00 0x20>;
		phandle = <0x71>;
	};

	qos@ffab8000 {
		compatible = "rockchip,rk3399-qos\0syscon";
		reg = <0x00 0xffab8000 0x00 0x20>;
		phandle = <0x72>;
	};

	qos@ffac0000 {
		compatible = "rockchip,rk3399-qos\0syscon";
		reg = <0x00 0xffac0000 0x00 0x20>;
		phandle = <0x73>;
	};

	qos@ffac0080 {
		compatible = "rockchip,rk3399-qos\0syscon";
		reg = <0x00 0xffac0080 0x00 0x20>;
		phandle = <0x74>;
	};

	qos@ffac8000 {
		compatible = "rockchip,rk3399-qos\0syscon";
		reg = <0x00 0xffac8000 0x00 0x20>;
		phandle = <0x81>;
	};

	qos@ffac8080 {
		compatible = "rockchip,rk3399-qos\0syscon";
		reg = <0x00 0xffac8080 0x00 0x20>;
		phandle = <0x82>;
	};

	qos@ffad0000 {
		compatible = "rockchip,rk3399-qos\0syscon";
		reg = <0x00 0xffad0000 0x00 0x20>;
		phandle = <0x83>;
	};

	qos@ffad8080 {
		compatible = "rockchip,rk3399-qos\0syscon";
		reg = <0x00 0xffad8080 0x00 0x20>;
		phandle = <0x107>;
	};

	qos@ffae0000 {
		compatible = "rockchip,rk3399-qos\0syscon";
		reg = <0x00 0xffae0000 0x00 0x20>;
		phandle = <0x75>;
	};

	power-management@ff310000 {
		compatible = "rockchip,rk3399-pmu\0syscon\0simple-mfd";
		reg = <0x00 0xff310000 0x00 0x1000>;
		phandle = <0x108>;

		power-controller {
			compatible = "rockchip,rk3399-power-controller";
			#power-domain-cells = <0x01>;
			#address-cells = <0x01>;
			#size-cells = <0x00>;
			phandle = <0x18>;

			power-domain@34 {
				reg = <0x22>;
				clocks = <0x08 0xe1 0x08 0x1dd>;
				pm_qos = <0x6f>;
				#power-domain-cells = <0x00>;
			};

			power-domain@33 {
				reg = <0x21>;
				clocks = <0x08 0xdc 0x08 0x1e5>;
				pm_qos = <0x70 0x71>;
				#power-domain-cells = <0x00>;
			};

			power-domain@31 {
				reg = <0x1f>;
				clocks = <0x08 0xeb 0x08 0x1ea>;
				pm_qos = <0x72>;
				#power-domain-cells = <0x00>;
			};

			power-domain@32 {
				reg = <0x20>;
				clocks = <0x08 0xed 0x08 0x1ec 0x08 0x9f 0x08 0x9e>;
				pm_qos = <0x73 0x74>;
				#power-domain-cells = <0x00>;
			};

			power-domain@35 {
				reg = <0x23>;
				clocks = <0x08 0xd0>;
				pm_qos = <0x75>;
				#power-domain-cells = <0x00>;
			};

			power-domain@25 {
				reg = <0x19>;
				clocks = <0x08 0x16c>;
				#power-domain-cells = <0x00>;
			};

			power-domain@23 {
				reg = <0x17>;
				clocks = <0x08 0xf0>;
				pm_qos = <0x76>;
				#power-domain-cells = <0x00>;
			};

			power-domain@22 {
				reg = <0x16>;
				clocks = <0x08 0xd5 0x08 0x166>;
				pm_qos = <0x77>;
				#power-domain-cells = <0x00>;
			};

			power-domain@27 {
				reg = <0x1b>;
				clocks = <0x08 0x1ce 0x08 0x4c>;
				pm_qos = <0x78>;
				#power-domain-cells = <0x00>;
			};

			power-domain@28 {
				reg = <0x1c>;
				clocks = <0x08 0x1ee>;
				pm_qos = <0x79>;
				#power-domain-cells = <0x00>;
			};

			power-domain@8 {
				reg = <0x08>;
				clocks = <0x08 0x7e 0x08 0x7d>;
				#power-domain-cells = <0x00>;
			};

			power-domain@9 {
				reg = <0x09>;
				clocks = <0x08 0x80 0x08 0x7f>;
				#power-domain-cells = <0x00>;
			};

			power-domain@24 {
				reg = <0x18>;
				clocks = <0x08 0xf4>;
				pm_qos = <0x7a 0x7b>;
				#power-domain-cells = <0x00>;
			};

			power-domain@15 {
				reg = <0x0f>;
				#power-domain-cells = <0x01>;
				#address-cells = <0x01>;
				#size-cells = <0x00>;

				power-domain@21 {
					reg = <0x15>;
					clocks = <0x08 0xde 0x08 0x1e7 0x08 0x172>;
					pm_qos = <0x7c>;
					#power-domain-cells = <0x00>;
				};

				power-domain@19 {
					reg = <0x13>;
					clocks = <0x08 0xe5 0x08 0x1df>;
					pm_qos = <0x7d 0x7e>;
					#power-domain-cells = <0x00>;
				};

				power-domain@20 {
					reg = <0x14>;
					clocks = <0x08 0xe6 0x08 0x1e0>;
					pm_qos = <0x7f 0x80>;
					#power-domain-cells = <0x00>;
				};

				power-domain@16 {
					reg = <0x10>;
					#power-domain-cells = <0x01>;
					#address-cells = <0x01>;
					#size-cells = <0x00>;

					power-domain@17 {
						reg = <0x11>;
						clocks = <0x08 0xd9 0x08 0x1d9>;
						pm_qos = <0x81 0x82>;
						#power-domain-cells = <0x00>;
					};

					power-domain@18 {
						reg = <0x12>;
						clocks = <0x08 0xdb 0x08 0x1db>;
						pm_qos = <0x83>;
						#power-domain-cells = <0x00>;
					};
				};
			};
		};
	};

	syscon@ff320000 {
		compatible = "rockchip,rk3399-pmugrf\0syscon\0simple-mfd";
		reg = <0x00 0xff320000 0x00 0x1000>;
		phandle = <0x11>;

		io-domains {
			compatible = "rockchip,rk3399-pmu-io-voltage-domain";
			status = "okay";
			pmu1830-supply = <0x84>;
			phandle = <0x109>;
		};
	};

	spi@ff350000 {
		compatible = "rockchip,rk3399-spi\0rockchip,rk3066-spi";
		reg = <0x00 0xff350000 0x00 0x1000>;
		clocks = <0x85 0x03 0x85 0x1f>;
		clock-names = "spiclk\0apb_pclk";
		interrupts = <0x00 0x3c 0x04 0x00>;
		pinctrl-names = "default";
		pinctrl-0 = <0x86 0x87 0x88 0x89>;
		#address-cells = <0x01>;
		#size-cells = <0x00>;
		status = "disabled";
		phandle = <0x10a>;
	};

	serial@ff370000 {
		compatible = "rockchip,rk3399-uart\0snps,dw-apb-uart";
		reg = <0x00 0xff370000 0x00 0x100>;
		clocks = <0x85 0x06 0x85 0x22>;
		clock-names = "baudclk\0apb_pclk";
		interrupts = <0x00 0x66 0x04 0x00>;
		reg-shift = <0x02>;
		reg-io-width = <0x04>;
		pinctrl-names = "default";
		pinctrl-0 = <0x8a>;
		status = "okay";
		phandle = <0x10b>;
	};

	i2c@ff3c0000 {
		compatible = "rockchip,rk3399-i2c";
		reg = <0x00 0xff3c0000 0x00 0x1000>;
		assigned-clocks = <0x85 0x09>;
		assigned-clock-rates = <0xbebc200>;
		clocks = <0x85 0x09 0x85 0x1b>;
		clock-names = "i2c\0pclk";
		interrupts = <0x00 0x39 0x04 0x00>;
		pinctrl-names = "default";
		pinctrl-0 = <0x8b>;
		#address-cells = <0x01>;
		#size-cells = <0x00>;
		status = "okay";
		i2c-scl-rising-time-ns = <0xa8>;
		i2c-scl-falling-time-ns = <0x04>;
		clock-frequency = <0x61a80>;
		phandle = <0x10c>;

		syr827@40 {
			compatible = "silergy,syr827";
			reg = <0x40>;
			vin-supply = <0x4e>;
			regulator-compatible = "fan53555-reg";
			pinctrl-0 = <0x8c>;
			vsel-gpios = <0x38 0x11 0x00>;
			regulator-name = "vdd_cpu_b";
			regulator-min-microvolt = <0xadf34>;
			regulator-max-microvolt = <0x16e360>;
			regulator-ramp-delay = <0x3e8>;
			fcs,suspend-voltage-selector = <0x01>;
			regulator-always-on;
			regulator-boot-on;
			regulator-initial-state = <0x03>;
			phandle = <0x0e>;

			regulator-state-mem {
				regulator-off-in-suspend;
			};
		};

		syr828@41 {
			compatible = "silergy,syr828";
			reg = <0x41>;
			vin-supply = <0x4e>;
			regulator-compatible = "fan53555-reg";
			pinctrl-names = "default";
			pinctrl-0 = <0x8d>;
			vsel-gpios = <0x38 0x0e 0x00>;
			regulator-name = "vdd_gpu";
			regulator-min-microvolt = <0xadf34>;
			regulator-max-microvolt = <0x16e360>;
			regulator-ramp-delay = <0x3e8>;
			fcs,suspend-voltage-selector = <0x01>;
			regulator-always-on;
			regulator-boot-on;
			regulator-initial-state = <0x03>;
			phandle = <0xc5>;

			regulator-state-mem {
				regulator-off-in-suspend;
			};
		};

		pmic@1b {
			compatible = "rockchip,rk808";
			reg = <0x1b>;
			interrupt-parent = <0x38>;
			interrupts = <0x15 0x08>;
			pinctrl-names = "default";
			pinctrl-0 = <0x8e>;
			rockchip,system-power-controller;
			wakeup-source;
			#clock-cells = <0x01>;
			clock-output-names = "xin32k\0rk808-clkout2";
			vcc1-supply = <0x8f>;
			vcc2-supply = <0x8f>;
			vcc3-supply = <0x8f>;
			vcc4-supply = <0x8f>;
			vcc6-supply = <0x8f>;
			vcc7-supply = <0x8f>;
			vcc8-supply = <0x36>;
			vcc9-supply = <0x8f>;
			vcc10-supply = <0x8f>;
			vcc11-supply = <0x8f>;
			vcc12-supply = <0x90>;
			vddio-supply = <0x84>;
			phandle = <0x4a>;

			rtc {
				status = "okay";
			};

			regulators {

				DCDC_REG1 {
					regulator-always-on;
					regulator-boot-on;
					regulator-min-microvolt = <0xb71b0>;
					regulator-max-microvolt = <0x149970>;
					regulator-ramp-delay = <0x1771>;
					regulator-name = "vdd_center";
					phandle = <0x10d>;

					regulator-state-mem {
						regulator-off-in-suspend;
					};
				};

				DCDC_REG2 {
					regulator-always-on;
					regulator-boot-on;
					regulator-min-microvolt = <0xb71b0>;
					regulator-max-microvolt = <0x149970>;
					regulator-ramp-delay = <0x1771>;
					regulator-name = "vdd_cpu_l";
					phandle = <0x0c>;

					regulator-state-mem {
						regulator-off-in-suspend;
					};
				};

				DCDC_REG3 {
					regulator-always-on;
					regulator-boot-on;
					regulator-name = "vcc_ddr";
					phandle = <0x10e>;

					regulator-state-mem {
						regulator-on-in-suspend;
					};
				};

				DCDC_REG4 {
					regulator-always-on;
					regulator-boot-on;
					regulator-min-microvolt = <0x1b7740>;
					regulator-max-microvolt = <0x1b7740>;
					regulator-name = "vcc_1v8";
					phandle = <0x36>;

					regulator-state-mem {
						regulator-on-in-suspend;
						regulator-suspend-microvolt = <0x1b7740>;
					};
				};

				LDO_REG1 {
					regulator-always-on;
					regulator-boot-on;
					regulator-min-microvolt = <0x1b7740>;
					regulator-max-microvolt = <0x1b7740>;
					regulator-name = "vcc1v8_dvp";
					phandle = <0x10f>;

					regulator-state-mem {
						regulator-off-in-suspend;
					};
				};

				LDO_REG2 {
					regulator-name = "vcc1v8_hdmi";
					regulator-always-on;
					regulator-boot-on;
					regulator-min-microvolt = <0x1b7740>;
					regulator-max-microvolt = <0x1b7740>;
					phandle = <0xb9>;

					regulator-state-mem {
						regulator-on-in-suspend;
						regulator-suspend-microvolt = <0x1b7740>;
					};
				};

				LDO_REG3 {
					regulator-always-on;
					regulator-boot-on;
					regulator-min-microvolt = <0x1b7740>;
					regulator-max-microvolt = <0x1b7740>;
					regulator-name = "vcc1v8_pmu";
					phandle = <0x110>;

					regulator-state-mem {
						regulator-on-in-suspend;
						regulator-suspend-microvolt = <0x1b7740>;
					};
				};

				LDO_REG4 {
					regulator-always-on;
					regulator-boot-on;
					regulator-min-microvolt = <0x1b7740>;
					regulator-max-microvolt = <0x2dc6c0>;
					regulator-name = "vcc_sdio";
					phandle = <0x27>;

					regulator-state-mem {
						regulator-on-in-suspend;
						regulator-suspend-microvolt = <0x2dc6c0>;
					};
				};

				LDO_REG5 {
					regulator-always-on;
					regulator-boot-on;
					regulator-min-microvolt = <0x2dc6c0>;
					regulator-max-microvolt = <0x2dc6c0>;
					regulator-name = "vcca3v0_codec";
					phandle = <0x111>;

					regulator-state-mem {
						regulator-off-in-suspend;
					};
				};

				LDO_REG6 {
					regulator-always-on;
					regulator-boot-on;
					regulator-min-microvolt = <0x16e360>;
					regulator-max-microvolt = <0x16e360>;
					regulator-name = "vcc_1v5";
					phandle = <0x112>;

					regulator-state-mem {
						regulator-on-in-suspend;
						regulator-suspend-microvolt = <0x16e360>;
					};
				};

				LDO_REG7 {
					regulator-name = "vcca0v9_hdmi";
					regulator-always-on;
					regulator-boot-on;
					regulator-min-microvolt = <0xdbba0>;
					regulator-max-microvolt = <0xdbba0>;
					phandle = <0xb8>;

					regulator-state-mem {
						regulator-on-in-suspend;
						regulator-suspend-microvolt = <0xdbba0>;
					};
				};

				LDO_REG8 {
					regulator-always-on;
					regulator-boot-on;
					regulator-min-microvolt = <0x2dc6c0>;
					regulator-max-microvolt = <0x2dc6c0>;
					regulator-name = "vcc_3v0";
					phandle = <0x84>;

					regulator-state-mem {
						regulator-on-in-suspend;
						regulator-suspend-microvolt = <0x2dc6c0>;
					};
				};

				SWITCH_REG1 {
					regulator-always-on;
					regulator-boot-on;
					regulator-name = "vcc3v3_s3";
					phandle = <0x1a>;

					regulator-state-mem {
						regulator-on-in-suspend;
					};
				};

				SWITCH_REG2 {
					regulator-always-on;
					regulator-boot-on;
					regulator-name = "vcc3v3_s0";
					phandle = <0x113>;

					regulator-state-mem {
						regulator-on-in-suspend;
					};
				};
			};
		};

		rtc_hym8563@51 {
			status = "okay";
			compatible = "rtc,hym8563";
			reg = <0x51>;
			phandle = <0x114>;
		};

		pt7c4337@68 {
			status = "okay";
			compatible = "pericom,pt7c4337";
			reg = <0x68>;
			phandle = <0x115>;
		};
	};

	i2c@ff3d0000 {
		compatible = "rockchip,rk3399-i2c";
		reg = <0x00 0xff3d0000 0x00 0x1000>;
		assigned-clocks = <0x85 0x0a>;
		assigned-clock-rates = <0xbebc200>;
		clocks = <0x85 0x0a 0x85 0x1c>;
		clock-names = "i2c\0pclk";
		interrupts = <0x00 0x38 0x04 0x00>;
		pinctrl-names = "default";
		pinctrl-0 = <0x91>;
		#address-cells = <0x01>;
		#size-cells = <0x00>;
		status = "okay";
		i2c-scl-rising-time-ns = <0x258>;
		i2c-scl-falling-time-ns = <0x14>;
		phandle = <0x116>;

		mma8452@1d {
			status = "okay";
			compatible = "gs_mma8452";
			reg = <0x1d>;
			type = <0x02>;
			irq-gpio = <0x92 0x1d 0x02>;
			pinctrl-names = "default";
			pinctrl-0 = <0x93>;
			irq_enable = <0x01>;
			poll_delay_ms = <0x1e>;
			layout = <0x08>;
			phandle = <0x117>;
		};

		tc358775@f {
			compatible = "signway,tc358775-i2c";
			reg = <0x0f>;
			phandle = <0x118>;
		};
	};

	i2c@ff3e0000 {
		compatible = "rockchip,rk3399-i2c";
		reg = <0x00 0xff3e0000 0x00 0x1000>;
		assigned-clocks = <0x85 0x0b>;
		assigned-clock-rates = <0xbebc200>;
		clocks = <0x85 0x0b 0x85 0x1d>;
		clock-names = "i2c\0pclk";
		interrupts = <0x00 0x3a 0x04 0x00>;
		pinctrl-names = "default";
		pinctrl-0 = <0x94>;
		#address-cells = <0x01>;
		#size-cells = <0x00>;
		status = "disabled";
		phandle = <0x119>;
	};

	pwm@ff420000 {
		compatible = "rockchip,rk3399-pwm\0rockchip,rk3288-pwm";
		reg = <0x00 0xff420000 0x00 0x10>;
		#pwm-cells = <0x03>;
		pinctrl-names = "default";
		pinctrl-0 = <0x95>;
		clocks = <0x85 0x1e>;
		status = "okay";
		phandle = <0xdb>;
	};

	pwm@ff420010 {
		compatible = "rockchip,rk3399-pwm\0rockchip,rk3288-pwm";
		reg = <0x00 0xff420010 0x00 0x10>;
		#pwm-cells = <0x03>;
		pinctrl-names = "default";
		pinctrl-0 = <0x96>;
		clocks = <0x85 0x1e>;
		status = "okay";
		phandle = <0x11a>;
	};

	pwm@ff420020 {
		compatible = "rockchip,rk3399-pwm\0rockchip,rk3288-pwm";
		reg = <0x00 0xff420020 0x00 0x10>;
		#pwm-cells = <0x03>;
		pinctrl-names = "default";
		pinctrl-0 = <0x97>;
		clocks = <0x85 0x1e>;
		status = "okay";
		phandle = <0xcc>;
	};

	pwm@ff420030 {
		compatible = "rockchip,remotectl-pwm";
		reg = <0x00 0xff420030 0x00 0x10>;
		#pwm-cells = <0x03>;
		pinctrl-names = "default";
		pinctrl-0 = <0x98>;
		clocks = <0x85 0x1e>;
		status = "disabled";
		interrupts = <0x00 0x3d 0x04 0x00>;
		remote_pwm_id = <0x03>;
		handle_cpu_id = <0x01>;
		phandle = <0x11b>;

		ir_key1 {
			rockchip,usercode = <0xff00>;
			rockchip,key_table = <0xba 0x57 0xae 0x43 0xb9 0x8b 0xad 0x42 0xb6 0x3b 0xb2 0x3c 0xaa 0x3d 0xa6 0x3e 0xe6 0x67 0xe3 0x6c 0xf3 0x69 0xa1 0x6a 0xe7 0x1c 0xb8 0x44 0xea 0x73 0xf6 0x72 0xf8 0x71 0xfb 0x02 0xfa 0x03 0xf9 0x04 0xeb 0x05 0xe9 0x06 0xe8 0x07 0xf7 0x08 0xf5 0x09 0xf4 0x0a 0xf1 0x0b 0xb5 0x0f 0xb7 0xac 0xa4 0x9e 0xb3 0x40 0xf0 0x3f 0xf2 0x41>;
		};
	};

	dfi@ff630000 {
		reg = <0x00 0xff630000 0x00 0x4000>;
		compatible = "rockchip,rk3399-dfi";
		rockchip,pmu = <0x11>;
		interrupts = <0x00 0x83 0x04 0x00>;
		clocks = <0x08 0x179>;
		clock-names = "pclk_ddr_mon";
		status = "okay";
		phandle = <0x12>;
	};

	video-codec@ff650000 {
		compatible = "rockchip,rk3399-vpu";
		reg = <0x00 0xff650000 0x00 0x800>;
		interrupts = <0x00 0x72 0x04 0x00 0x00 0x71 0x04 0x00>;
		interrupt-names = "vepu\0vdpu";
		clocks = <0x08 0xeb 0x08 0x1ea>;
		clock-names = "aclk\0hclk";
		iommus = <0x99>;
		power-domains = <0x18 0x1f>;
		status = "okay";
		phandle = <0x11c>;
	};

	iommu@ff650800 {
		compatible = "rockchip,iommu";
		reg = <0x00 0xff650800 0x00 0x40>;
		interrupts = <0x00 0x73 0x04 0x00>;
		clocks = <0x08 0xeb 0x08 0x1ea>;
		clock-names = "aclk\0iface";
		#iommu-cells = <0x00>;
		power-domains = <0x18 0x1f>;
		status = "okay";
		phandle = <0x99>;
	};

	video-codec@ff660000 {
		compatible = "rockchip,rk3399-vdec";
		reg = <0x00 0xff660000 0x00 0x480>;
		interrupts = <0x00 0x74 0x04 0x00>;
		clocks = <0x08 0xed 0x08 0x1ec 0x08 0x9f 0x08 0x9e>;
		clock-names = "axi\0ahb\0cabac\0core";
		iommus = <0x9a>;
		power-domains = <0x18 0x20>;
		status = "okay";
		phandle = <0x11d>;
	};

	iommu@ff660480 {
		compatible = "rockchip,iommu";
		reg = <0x00 0xff660480 0x00 0x40 0x00 0xff6604c0 0x00 0x40>;
		interrupts = <0x00 0x75 0x04 0x00>;
		clocks = <0x08 0xed 0x08 0x1ec>;
		clock-names = "aclk\0iface";
		power-domains = <0x18 0x20>;
		#iommu-cells = <0x00>;
		status = "okay";
		phandle = <0x9a>;
	};

	iommu@ff670800 {
		compatible = "rockchip,iommu";
		reg = <0x00 0xff670800 0x00 0x40>;
		interrupts = <0x00 0x2a 0x04 0x00>;
		clocks = <0x08 0xe1 0x08 0x1dd>;
		clock-names = "aclk\0iface";
		#iommu-cells = <0x00>;
		status = "okay";
		phandle = <0x11e>;
	};

	rga@ff680000 {
		compatible = "rockchip,rk3399-rga";
		reg = <0x00 0xff680000 0x00 0x10000>;
		interrupts = <0x00 0x37 0x04 0x00>;
		clocks = <0x08 0xdc 0x08 0x1e5 0x08 0x6d>;
		clock-names = "aclk\0hclk\0sclk";
		resets = <0x08 0x6a 0x08 0x67 0x08 0x69>;
		reset-names = "core\0axi\0ahb";
		power-domains = <0x18 0x21>;
		status = "okay";
		phandle = <0x11f>;
	};

	efuse@ff690000 {
		compatible = "rockchip,rk3399-efuse";
		reg = <0x00 0xff690000 0x00 0x80>;
		#address-cells = <0x01>;
		#size-cells = <0x01>;
		clocks = <0x08 0x17d>;
		clock-names = "pclk_efuse";
		phandle = <0x120>;

		cpu-id@7 {
			reg = <0x07 0x10>;
			phandle = <0x121>;
		};

		cpu-leakage@17 {
			reg = <0x17 0x01>;
			phandle = <0x122>;
		};

		gpu-leakage@18 {
			reg = <0x18 0x01>;
			phandle = <0x123>;
		};

		center-leakage@19 {
			reg = <0x19 0x01>;
			phandle = <0x124>;
		};

		cpu-leakage@1a {
			reg = <0x1a 0x01>;
			phandle = <0x125>;
		};

		logic-leakage@1b {
			reg = <0x1b 0x01>;
			phandle = <0x126>;
		};

		wafer-info@1c {
			reg = <0x1c 0x01>;
			phandle = <0x127>;
		};
	};

	dma-controller@ff6d0000 {
		compatible = "arm,pl330\0arm,primecell";
		reg = <0x00 0xff6d0000 0x00 0x4000>;
		interrupts = <0x00 0x05 0x04 0x00 0x00 0x06 0x04 0x00>;
		#dma-cells = <0x01>;
		arm,pl330-periph-burst;
		clocks = <0x08 0xd3>;
		clock-names = "apb_pclk";
		phandle = <0x63>;
	};

	dma-controller@ff6e0000 {
		compatible = "arm,pl330\0arm,primecell";
		reg = <0x00 0xff6e0000 0x00 0x4000>;
		interrupts = <0x00 0x07 0x04 0x00 0x00 0x08 0x04 0x00>;
		#dma-cells = <0x01>;
		arm,pl330-periph-burst;
		clocks = <0x08 0xd4>;
		clock-names = "apb_pclk";
		phandle = <0x52>;
	};

	clock-controller@ff750000 {
		compatible = "rockchip,rk3399-pmucru";
		reg = <0x00 0xff750000 0x00 0x1000>;
		clocks = <0x9b>;
		clock-names = "xin24m";
		rockchip,grf = <0x11>;
		#clock-cells = <0x01>;
		#reset-cells = <0x01>;
		assigned-clocks = <0x85 0x01>;
		assigned-clock-rates = <0x284af100>;
		phandle = <0x85>;
	};

	clock-controller@ff760000 {
		compatible = "rockchip,rk3399-cru";
		reg = <0x00 0xff760000 0x00 0x1000>;
		clocks = <0x9b>;
		clock-names = "xin24m";
		rockchip,grf = <0x19>;
		#clock-cells = <0x01>;
		#reset-cells = <0x01>;
		assigned-clocks = <0x08 0x05 0x08 0x04 0x08 0x06 0x08 0xc0 0x08 0x1c0 0x08 0x140 0x08 0xc2 0x08 0x1c1 0x08 0x142 0x08 0xc9 0x08 0x1c2 0x08 0x143 0x08 0xe3 0x08 0xde 0x08 0x106 0x08 0x178 0x08 0xed>;
		assigned-clock-rates = <0x2367b880 0x2faf0800 0x3b9aca00 0x8f0d180 0x47868c0 0x23c3460 0x5f5e100 0x5f5e100 0x2faf080 0x23c34600 0x5f5e100 0x2faf080 0x17d78400 0x17d78400 0xbebc200 0xbebc200 0x17d78400>;
		phandle = <0x08>;
	};

	syscon@ff770000 {
		compatible = "rockchip,rk3399-grf\0syscon\0simple-mfd";
		reg = <0x00 0xff770000 0x00 0x10000>;
		#address-cells = <0x01>;
		#size-cells = <0x01>;
		phandle = <0x19>;

		io-domains {
			compatible = "rockchip,rk3399-io-voltage-domain";
			status = "okay";
			bt656-supply = <0x36>;
			audio-supply = <0x84>;
			sdmmc-supply = <0x27>;
			gpio1830-supply = <0x84>;
			wifi-supply = <0x90>;
			phandle = <0x128>;
		};

		mipi-dphy-rx0 {
			compatible = "rockchip,rk3399-mipi-dphy-rx0";
			clocks = <0x08 0x77 0x08 0xa5 0x08 0x16f>;
			clock-names = "dphy-ref\0dphy-cfg\0grf";
			power-domains = <0x18 0x0f>;
			#phy-cells = <0x00>;
			status = "disabled";
			phandle = <0xb3>;
		};

		usb2phy@e450 {
			compatible = "rockchip,rk3399-usb2phy";
			reg = <0xe450 0x10>;
			clocks = <0x08 0x7b>;
			clock-names = "phyclk";
			#clock-cells = <0x00>;
			clock-output-names = "clk_usbphy0_480m";
			status = "okay";
			phandle = <0x2a>;

			host-port {
				#phy-cells = <0x00>;
				interrupts = <0x00 0x1b 0x04 0x00>;
				interrupt-names = "linestate";
				status = "okay";
				phy-supply = <0x9c>;
				phandle = <0x2b>;
			};

			otg-port {
				#phy-cells = <0x00>;
				interrupts = <0x00 0x67 0x04 0x00 0x00 0x68 0x04 0x00 0x00 0x6a 0x04 0x00>;
				interrupt-names = "otg-bvalid\0otg-id\0linestate";
				status = "okay";
				phandle = <0x2e>;
			};

			port {

				endpoint {
					remote-endpoint = <0x9d>;
					phandle = <0x40>;
				};
			};
		};

		usb2phy@e460 {
			compatible = "rockchip,rk3399-usb2phy";
			reg = <0xe460 0x10>;
			clocks = <0x08 0x7c>;
			clock-names = "phyclk";
			#clock-cells = <0x00>;
			clock-output-names = "clk_usbphy1_480m";
			status = "okay";
			phandle = <0x2c>;

			host-port {
				#phy-cells = <0x00>;
				interrupts = <0x00 0x1f 0x04 0x00>;
				interrupt-names = "linestate";
				status = "okay";
				phy-supply = <0x9c>;
				phandle = <0x2d>;
			};

			otg-port {
				#phy-cells = <0x00>;
				interrupts = <0x00 0x6c 0x04 0x00 0x00 0x6d 0x04 0x00 0x00 0x6f 0x04 0x00>;
				interrupt-names = "otg-bvalid\0otg-id\0linestate";
				status = "okay";
				phandle = <0x30>;
			};
		};

		phy@f780 {
			compatible = "rockchip,rk3399-emmc-phy";
			reg = <0xf780 0x24>;
			clocks = <0x9e>;
			clock-names = "emmcclk";
			drive-impedance-ohm = <0x32>;
			#phy-cells = <0x00>;
			status = "okay";
			phandle = <0x29>;
		};

		pcie-phy {
			compatible = "rockchip,rk3399-pcie-phy";
			clocks = <0x08 0x8a>;
			clock-names = "refclk";
			#phy-cells = <0x01>;
			resets = <0x08 0x87>;
			reset-names = "phy";
			status = "disabled";
			phandle = <0x17>;
		};
	};

	phy@ff7c0000 {
		compatible = "rockchip,rk3399-typec-phy";
		reg = <0x00 0xff7c0000 0x00 0x40000>;
		clocks = <0x08 0x7e 0x08 0x7d>;
		clock-names = "tcpdcore\0tcpdphy-ref";
		assigned-clocks = <0x08 0x7e>;
		assigned-clock-rates = <0x2faf080>;
		power-domains = <0x18 0x08>;
		resets = <0x08 0x95 0x08 0x94 0x08 0x14c>;
		reset-names = "uphy\0uphy-pipe\0uphy-tcphy";
		rockchip,grf = <0x19>;
		status = "okay";
		phandle = <0x129>;

		dp-port {
			#phy-cells = <0x00>;
			phandle = <0x32>;

			port {

				endpoint {
					remote-endpoint = <0x9f>;
					phandle = <0x42>;
				};
			};
		};

		usb3-port {
			#phy-cells = <0x00>;
			phandle = <0x2f>;

			port {

				endpoint {
					remote-endpoint = <0xa0>;
					phandle = <0x41>;
				};
			};
		};
	};

	phy@ff800000 {
		compatible = "rockchip,rk3399-typec-phy";
		reg = <0x00 0xff800000 0x00 0x40000>;
		clocks = <0x08 0x80 0x08 0x7f>;
		clock-names = "tcpdcore\0tcpdphy-ref";
		assigned-clocks = <0x08 0x80>;
		assigned-clock-rates = <0x2faf080>;
		power-domains = <0x18 0x09>;
		resets = <0x08 0x9d 0x08 0x9c 0x08 0x14d>;
		reset-names = "uphy\0uphy-pipe\0uphy-tcphy";
		rockchip,grf = <0x19>;
		status = "okay";
		phandle = <0x12a>;

		dp-port {
			#phy-cells = <0x00>;
			phandle = <0x33>;
		};

		usb3-port {
			#phy-cells = <0x00>;
			phandle = <0x31>;
		};
	};

	watchdog@ff848000 {
		compatible = "rockchip,rk3399-wdt\0snps,dw-wdt";
		reg = <0x00 0xff848000 0x00 0x100>;
		clocks = <0x08 0x17c>;
		interrupts = <0x00 0x78 0x04 0x00>;
	};

	rktimer@ff850000 {
		compatible = "rockchip,rk3399-timer";
		reg = <0x00 0xff850000 0x00 0x1000>;
		interrupts = <0x00 0x51 0x04 0x00>;
		clocks = <0x08 0x168 0x08 0x5a>;
		clock-names = "pclk\0timer";
		phandle = <0x12b>;
	};

	spdif@ff870000 {
		compatible = "rockchip,rk3399-spdif";
		reg = <0x00 0xff870000 0x00 0x1000>;
		interrupts = <0x00 0x42 0x04 0x00>;
		dmas = <0x63 0x07>;
		dma-names = "tx";
		clock-names = "mclk\0hclk";
		clocks = <0x08 0x55 0x08 0x1d7>;
		pinctrl-names = "default";
		pinctrl-0 = <0xa1>;
		power-domains = <0x18 0x1c>;
		#sound-dai-cells = <0x00>;
		status = "okay";
		i2c-scl-rising-time-ns = <0x1c2>;
		i2c-scl-falling-time-ns = <0x0f>;
		phandle = <0x12c>;
	};

	i2s@ff880000 {
		compatible = "rockchip,rk3399-i2s\0rockchip,rk3066-i2s";
		reg = <0x00 0xff880000 0x00 0x1000>;
		rockchip,grf = <0x19>;
		interrupts = <0x00 0x27 0x04 0x00>;
		dmas = <0x63 0x00 0x63 0x01>;
		dma-names = "tx\0rx";
		clock-names = "i2s_clk\0i2s_hclk";
		clocks = <0x08 0x56 0x08 0x1d4>;
		pinctrl-names = "bclk_on\0bclk_off";
		pinctrl-0 = <0xa2 0xa3>;
		pinctrl-1 = <0xa4>;
		power-domains = <0x18 0x1c>;
		#sound-dai-cells = <0x00>;
		status = "okay";
		rockchip,playback-channels = <0x08>;
		rockchip,capture-channels = <0x08>;
		phandle = <0xd8>;
	};

	i2s@ff890000 {
		compatible = "rockchip,rk3399-i2s\0rockchip,rk3066-i2s";
		reg = <0x00 0xff890000 0x00 0x1000>;
		interrupts = <0x00 0x28 0x04 0x00>;
		dmas = <0x63 0x02 0x63 0x03>;
		dma-names = "tx\0rx";
		clock-names = "i2s_clk\0i2s_hclk";
		clocks = <0x08 0x57 0x08 0x1d5>;
		pinctrl-names = "default";
		pinctrl-0 = <0xa5>;
		power-domains = <0x18 0x1c>;
		#sound-dai-cells = <0x00>;
		status = "disabled";
		phandle = <0x12d>;
	};

	i2s@ff8a0000 {
		compatible = "rockchip,rk3399-i2s\0rockchip,rk3066-i2s";
		reg = <0x00 0xff8a0000 0x00 0x1000>;
		interrupts = <0x00 0x29 0x04 0x00>;
		dmas = <0x63 0x04 0x63 0x05>;
		dma-names = "tx\0rx";
		clock-names = "i2s_clk\0i2s_hclk";
		clocks = <0x08 0x58 0x08 0x1d6>;
		power-domains = <0x18 0x1c>;
		#sound-dai-cells = <0x00>;
		status = "disable";
		rockchip,bclk-fs = <0x80>;
		phandle = <0xb6>;
	};

	vop@ff8f0000 {
		compatible = "rockchip,rk3399-vop-lit";
		reg = <0x00 0xff8f0000 0x00 0x2000 0x00 0xff8f2000 0x00 0x400>;
		interrupts = <0x00 0x77 0x04 0x00>;
		assigned-clocks = <0x08 0xdb 0x08 0x1db>;
		assigned-clock-rates = <0x17d78400 0x5f5e100>;
		clocks = <0x08 0xdb 0x08 0xb5 0x08 0x1db>;
		clock-names = "aclk_vop\0dclk_vop\0hclk_vop";
		iommus = <0xa6>;
		power-domains = <0x18 0x12>;
		resets = <0x08 0x113 0x08 0x117 0x08 0x119>;
		reset-names = "axi\0ahb\0dclk";
		status = "okay";
		phandle = <0x12e>;

		port {
			#address-cells = <0x01>;
			#size-cells = <0x00>;
			phandle = <0x0f>;

			endpoint@0 {
				reg = <0x00>;
				remote-endpoint = <0xa7>;
				phandle = <0xbe>;
			};

			endpoint@1 {
				reg = <0x01>;
				remote-endpoint = <0xa8>;
				phandle = <0xc3>;
			};

			endpoint@2 {
				reg = <0x02>;
				remote-endpoint = <0xa9>;
				status = "disabled";
				phandle = <0xbc>;
			};

			endpoint@3 {
				reg = <0x03>;
				remote-endpoint = <0xaa>;
				phandle = <0xc0>;
			};

			endpoint@4 {
				reg = <0x04>;
				remote-endpoint = <0xab>;
				phandle = <0x35>;
			};
		};
	};

	iommu@ff8f3f00 {
		compatible = "rockchip,iommu";
		reg = <0x00 0xff8f3f00 0x00 0x100>;
		interrupts = <0x00 0x77 0x04 0x00>;
		clocks = <0x08 0xdb 0x08 0x1db>;
		clock-names = "aclk\0iface";
		power-domains = <0x18 0x12>;
		#iommu-cells = <0x00>;
		status = "okay";
		phandle = <0xa6>;
	};

	vop@ff900000 {
		compatible = "rockchip,rk3399-vop-big";
		reg = <0x00 0xff900000 0x00 0x2000 0x00 0xff902000 0x00 0x1000>;
		interrupts = <0x00 0x76 0x04 0x00>;
		assigned-clocks = <0x08 0xd9 0x08 0x1d9>;
		assigned-clock-rates = <0x17d78400 0x5f5e100>;
		clocks = <0x08 0xd9 0x08 0xb4 0x08 0x1d9>;
		clock-names = "aclk_vop\0dclk_vop\0hclk_vop";
		iommus = <0xac>;
		power-domains = <0x18 0x11>;
		resets = <0x08 0x112 0x08 0x116 0x08 0x118>;
		reset-names = "axi\0ahb\0dclk";
		status = "okay";
		phandle = <0x12f>;

		port {
			#address-cells = <0x01>;
			#size-cells = <0x00>;
			phandle = <0x10>;

			endpoint@0 {
				reg = <0x00>;
				remote-endpoint = <0xad>;
				phandle = <0xc2>;
			};

			endpoint@1 {
				reg = <0x01>;
				remote-endpoint = <0xae>;
				phandle = <0xbd>;
			};

			endpoint@2 {
				reg = <0x02>;
				remote-endpoint = <0xaf>;
				status = "okay";
				phandle = <0xbb>;
			};

			endpoint@3 {
				reg = <0x03>;
				remote-endpoint = <0xb0>;
				phandle = <0xbf>;
			};

			endpoint@4 {
				reg = <0x04>;
				remote-endpoint = <0xb1>;
				phandle = <0x34>;
			};
		};
	};

	iommu@ff903f00 {
		compatible = "rockchip,iommu";
		reg = <0x00 0xff903f00 0x00 0x100>;
		interrupts = <0x00 0x76 0x04 0x00>;
		clocks = <0x08 0xd9 0x08 0x1d9>;
		clock-names = "aclk\0iface";
		power-domains = <0x18 0x11>;
		#iommu-cells = <0x00>;
		status = "okay";
		phandle = <0xac>;
	};

	isp0@ff910000 {
		compatible = "rockchip,rk3399-cif-isp";
		reg = <0x00 0xff910000 0x00 0x4000>;
		interrupts = <0x00 0x2b 0x04 0x00>;
		clocks = <0x08 0x6e 0x08 0xe9 0x08 0x1e3>;
		clock-names = "isp\0aclk\0hclk";
		iommus = <0xb2>;
		phys = <0xb3>;
		phy-names = "dphy";
		power-domains = <0x18 0x13>;
		status = "disabled";
		phandle = <0x130>;

		ports {
			#address-cells = <0x01>;
			#size-cells = <0x00>;

			port@0 {
				reg = <0x00>;
				#address-cells = <0x01>;
				#size-cells = <0x00>;
			};
		};
	};

	iommu@ff914000 {
		compatible = "rockchip,iommu";
		reg = <0x00 0xff914000 0x00 0x100 0x00 0xff915000 0x00 0x100>;
		interrupts = <0x00 0x2b 0x04 0x00>;
		clocks = <0x08 0xe9 0x08 0x1e3>;
		clock-names = "aclk\0iface";
		#iommu-cells = <0x00>;
		power-domains = <0x18 0x13>;
		rockchip,disable-mmu-reset;
		phandle = <0xb2>;
	};

	isp1@ff920000 {
		compatible = "rockchip,rk3399-cif-isp";
		reg = <0x00 0xff920000 0x00 0x4000>;
		interrupts = <0x00 0x2c 0x04 0x00>;
		clocks = <0x08 0x6f 0x08 0xea 0x08 0x1e4>;
		clock-names = "isp\0aclk\0hclk";
		iommus = <0xb4>;
		phys = <0xb5>;
		phy-names = "dphy";
		power-domains = <0x18 0x14>;
		status = "disabled";
		phandle = <0x131>;

		ports {
			#address-cells = <0x01>;
			#size-cells = <0x00>;

			port@0 {
				reg = <0x00>;
				#address-cells = <0x01>;
				#size-cells = <0x00>;
			};
		};
	};

	iommu@ff924000 {
		compatible = "rockchip,iommu";
		reg = <0x00 0xff924000 0x00 0x100 0x00 0xff925000 0x00 0x100>;
		interrupts = <0x00 0x2c 0x04 0x00>;
		clocks = <0x08 0xea 0x08 0x1e4>;
		clock-names = "aclk\0iface";
		#iommu-cells = <0x00>;
		power-domains = <0x18 0x14>;
		rockchip,disable-mmu-reset;
		phandle = <0xb4>;
	};

	hdmi-sound {
		compatible = "simple-audio-card";
		simple-audio-card,format = "i2s";
		simple-audio-card,mclk-fs = <0x100>;
		simple-audio-card,name = "hdmi-sound";
		status = "disable";
		phandle = <0x132>;

		simple-audio-card,cpu {
			sound-dai = <0xb6>;
		};

		simple-audio-card,codec {
			sound-dai = <0xb7>;
		};
	};

	hdmi@ff940000 {
		compatible = "rockchip,rk3399-dw-hdmi";
		reg = <0x00 0xff940000 0x00 0x20000>;
		reg-io-width = <0x04>;
		interrupts = <0x00 0x17 0x04 0x00>;
		clocks = <0x08 0x174 0x08 0x71 0x08 0x70 0x08 0x16f 0x08 0x07>;
		clock-names = "iahb\0isfr\0cec\0grf\0ref";
		power-domains = <0x18 0x15>;
		rockchip,grf = <0x19>;
		#sound-dai-cells = <0x00>;
		status = "okay";
		avdd-0v9-supply = <0xb8>;
		avdd-1v8-supply = <0xb9>;
		ddc-i2c-scl-high-time-ns = <0x2599>;
		ddc-i2c-scl-low-time-ns = <0x2710>;
		pinctrl-names = "default";
		ddc-i2c-bus = <0xba>;
		phandle = <0xb7>;

		ports {
			#address-cells = <0x01>;
			#size-cells = <0x00>;

			port@0 {
				reg = <0x00>;
				#address-cells = <0x01>;
				#size-cells = <0x00>;
				phandle = <0x133>;

				endpoint@0 {
					reg = <0x00>;
					remote-endpoint = <0xbb>;
					phandle = <0xaf>;
				};

				endpoint@1 {
					reg = <0x01>;
					remote-endpoint = <0xbc>;
					phandle = <0xa9>;
				};
			};

			port@1 {
				reg = <0x01>;
				phandle = <0x134>;
			};
		};
	};

	mipi@ff960000 {
		compatible = "rockchip,rk3399-mipi-dsi\0snps,dw-mipi-dsi";
		reg = <0x00 0xff960000 0x00 0x8000>;
		interrupts = <0x00 0x2d 0x04 0x00>;
		clocks = <0x08 0xa2 0x08 0x170 0x08 0xa3 0x08 0x16f>;
		clock-names = "ref\0pclk\0phy_cfg\0grf";
		power-domains = <0x18 0x0f>;
		resets = <0x08 0xfb>;
		reset-names = "apb";
		rockchip,grf = <0x19>;
		#address-cells = <0x01>;
		#size-cells = <0x00>;
		status = "disabled";
		phandle = <0x135>;

		ports {
			#address-cells = <0x01>;
			#size-cells = <0x00>;

			port@0 {
				reg = <0x00>;
				#address-cells = <0x01>;
				#size-cells = <0x00>;
				phandle = <0x136>;

				endpoint@0 {
					reg = <0x00>;
					remote-endpoint = <0xbd>;
					phandle = <0xae>;
				};

				endpoint@1 {
					reg = <0x01>;
					remote-endpoint = <0xbe>;
					phandle = <0xa7>;
				};
			};
		};
	};

	mipi@ff968000 {
		compatible = "rockchip,rk3399-mipi-dsi\0snps,dw-mipi-dsi";
		reg = <0x00 0xff968000 0x00 0x8000>;
		interrupts = <0x00 0x2e 0x04 0x00>;
		clocks = <0x08 0xa2 0x08 0x171 0x08 0xa4 0x08 0x16f>;
		clock-names = "ref\0pclk\0phy_cfg\0grf";
		power-domains = <0x18 0x0f>;
		resets = <0x08 0xfc>;
		reset-names = "apb";
		rockchip,grf = <0x19>;
		#address-cells = <0x01>;
		#size-cells = <0x00>;
		#phy-cells = <0x00>;
		status = "disabled";
		phandle = <0xb5>;

		ports {
			#address-cells = <0x01>;
			#size-cells = <0x00>;

			port@0 {
				reg = <0x00>;
				#address-cells = <0x01>;
				#size-cells = <0x00>;
				phandle = <0x137>;

				endpoint@0 {
					reg = <0x00>;
					remote-endpoint = <0xbf>;
					phandle = <0xb0>;
				};

				endpoint@1 {
					reg = <0x01>;
					remote-endpoint = <0xc0>;
					phandle = <0xaa>;
				};
			};
		};
	};

	edp@ff970000 {
		compatible = "rockchip,rk3399-edp";
		reg = <0x00 0xff970000 0x00 0x8000>;
		interrupts = <0x00 0x0a 0x04 0x00>;
		clocks = <0x08 0x16a 0x08 0x16c 0x08 0x16f>;
		clock-names = "dp\0pclk\0grf";
		pinctrl-names = "default";
		pinctrl-0 = <0xc1>;
		power-domains = <0x18 0x19>;
		resets = <0x08 0x11d>;
		reset-names = "dp";
		rockchip,grf = <0x19>;
		status = "disabled";
		phandle = <0x138>;

		ports {
			#address-cells = <0x01>;
			#size-cells = <0x00>;

			port@0 {
				reg = <0x00>;
				#address-cells = <0x01>;
				#size-cells = <0x00>;
				phandle = <0x139>;

				endpoint@0 {
					reg = <0x00>;
					remote-endpoint = <0xc2>;
					phandle = <0xad>;
				};

				endpoint@1 {
					reg = <0x01>;
					remote-endpoint = <0xc3>;
					phandle = <0xa8>;
				};
			};
		};
	};

	rng@ff8b8000 {
		compatible = "rockchip,cryptov1-rng";
		reg = <0x00 0xff8b8000 0x00 0x1000>;
		clocks = <0x08 0x86 0x08 0x1d3>;
		clock-names = "clk_crypto\0hclk_crypto";
		assigned-clocks = <0x08 0x86 0x08 0x1d3>;
		assigned-clock-rates = <0x8f0d180 0x5f5e100>;
		status = "okay";
		phandle = <0x13a>;
	};

	gpu@ff9a0000 {
		compatible = "rockchip,rk3399-mali\0arm,mali-t860";
		reg = <0x00 0xff9a0000 0x00 0x10000>;
		interrupts = <0x00 0x14 0x04 0x00 0x00 0x15 0x04 0x00 0x00 0x13 0x04 0x00>;
		interrupt-names = "job\0mmu\0gpu";
		clocks = <0x08 0xd0>;
		#cooling-cells = <0x02>;
		power-domains = <0x18 0x23>;
		status = "okay";
		operating-points-v2 = <0xc4>;
		mali-supply = <0xc5>;
		phandle = <0x6c>;
	};

	pinctrl {
		compatible = "rockchip,rk3399-pinctrl";
		rockchip,grf = <0x19>;
		rockchip,pmu = <0x11>;
		#address-cells = <0x02>;
		#size-cells = <0x02>;
		ranges;
		phandle = <0x13b>;

		gpio@ff720000 {
			compatible = "rockchip,gpio-bank";
			reg = <0x00 0xff720000 0x00 0x100>;
			clocks = <0x85 0x17>;
			interrupts = <0x00 0x0e 0x04 0x00>;
			gpio-controller;
			#gpio-cells = <0x02>;
			interrupt-controller;
			#interrupt-cells = <0x02>;
			phandle = <0x22>;
		};

		gpio@ff730000 {
			compatible = "rockchip,gpio-bank";
			reg = <0x00 0xff730000 0x00 0x100>;
			clocks = <0x85 0x18>;
			interrupts = <0x00 0x0f 0x04 0x00>;
			gpio-controller;
			#gpio-cells = <0x02>;
			interrupt-controller;
			#interrupt-cells = <0x02>;
			phandle = <0x38>;
		};

		gpio@ff780000 {
			compatible = "rockchip,gpio-bank";
			reg = <0x00 0xff780000 0x00 0x100>;
			clocks = <0x08 0x150>;
			interrupts = <0x00 0x10 0x04 0x00>;
			gpio-controller;
			#gpio-cells = <0x02>;
			interrupt-controller;
			#interrupt-cells = <0x02>;
			phandle = <0x3e>;
		};

		gpio@ff788000 {
			compatible = "rockchip,gpio-bank";
			reg = <0x00 0xff788000 0x00 0x100>;
			clocks = <0x08 0x151>;
			interrupts = <0x00 0x11 0x04 0x00>;
			gpio-controller;
			#gpio-cells = <0x02>;
			interrupt-controller;
			#interrupt-cells = <0x02>;
			phandle = <0x1b>;
		};

		gpio@ff790000 {
			compatible = "rockchip,gpio-bank";
			reg = <0x00 0xff790000 0x00 0x100>;
			clocks = <0x08 0x152>;
			interrupts = <0x00 0x12 0x04 0x00>;
			gpio-controller;
			#gpio-cells = <0x02>;
			interrupt-controller;
			#interrupt-cells = <0x02>;
			phandle = <0x92>;
		};

		pcfg-pull-up {
			bias-pull-up;
			phandle = <0xc9>;
		};

		pcfg-pull-down {
			bias-pull-down;
			phandle = <0xca>;
		};

		pcfg-pull-none {
			bias-disable;
			phandle = <0xc6>;
		};

		pcfg-pull-none-12ma {
			bias-disable;
			drive-strength = <0x0c>;
			phandle = <0xc8>;
		};

		pcfg-pull-none-13ma {
			bias-disable;
			drive-strength = <0x0d>;
			phandle = <0xc7>;
		};

		pcfg-pull-none-18ma {
			bias-disable;
			drive-strength = <0x12>;
			phandle = <0x13c>;
		};

		pcfg-pull-none-20ma {
			bias-disable;
			drive-strength = <0x14>;
			phandle = <0x13d>;
		};

		pcfg-pull-up-2ma {
			bias-pull-up;
			drive-strength = <0x02>;
			phandle = <0x13e>;
		};

		pcfg-pull-up-8ma {
			bias-pull-up;
			drive-strength = <0x08>;
			phandle = <0x13f>;
		};

		pcfg-pull-up-18ma {
			bias-pull-up;
			drive-strength = <0x12>;
			phandle = <0x140>;
		};

		pcfg-pull-up-20ma {
			bias-pull-up;
			drive-strength = <0x14>;
			phandle = <0x141>;
		};

		pcfg-pull-down-4ma {
			bias-pull-down;
			drive-strength = <0x04>;
			phandle = <0x142>;
		};

		pcfg-pull-down-8ma {
			bias-pull-down;
			drive-strength = <0x08>;
			phandle = <0x143>;
		};

		pcfg-pull-down-12ma {
			bias-pull-down;
			drive-strength = <0x0c>;
			phandle = <0x144>;
		};

		pcfg-pull-down-18ma {
			bias-pull-down;
			drive-strength = <0x12>;
			phandle = <0x145>;
		};

		pcfg-pull-down-20ma {
			bias-pull-down;
			drive-strength = <0x14>;
			phandle = <0x146>;
		};

		pcfg-output-high {
			output-high;
			phandle = <0x147>;
		};

		pcfg-output-low {
			output-low;
			phandle = <0x148>;
		};

		pcfg-input-enable {
			input-enable;
			phandle = <0x149>;
		};

		pcfg-input-pull-up {
			input-enable;
			bias-pull-up;
			phandle = <0x14a>;
		};

		pcfg-input-pull-down {
			input-enable;
			bias-pull-down;
			phandle = <0x14b>;
		};

		clock {

			clk-32k {
				rockchip,pins = <0x00 0x00 0x02 0xc6>;
				phandle = <0x14c>;
			};
		};

		cif {

			cif-clkin {
				rockchip,pins = <0x02 0x0a 0x03 0xc6>;
				phandle = <0x14d>;
			};

			cif-clkouta {
				rockchip,pins = <0x02 0x0b 0x03 0xc6>;
				phandle = <0x14e>;
			};
		};

		edp {

			edp-hpd {
				rockchip,pins = <0x04 0x17 0x02 0xc6>;
				phandle = <0xc1>;
			};
		};

		gmac {

			rgmii-pins {
				rockchip,pins = <0x03 0x11 0x01 0xc7 0x03 0x0e 0x01 0xc6 0x03 0x0d 0x01 0xc6 0x03 0x0c 0x01 0xc7 0x03 0x0b 0x01 0xc6 0x03 0x09 0x01 0xc6 0x03 0x08 0x01 0xc6 0x03 0x07 0x01 0xc6 0x03 0x06 0x01 0xc6 0x03 0x05 0x01 0xc7 0x03 0x04 0x01 0xc7 0x03 0x03 0x01 0xc6 0x03 0x02 0x01 0xc6 0x03 0x01 0x01 0xc7 0x03 0x00 0x01 0xc7>;
				phandle = <0x1d>;
			};

			rmii-pins {
				rockchip,pins = <0x03 0x0d 0x01 0xc6 0x03 0x0c 0x01 0xc7 0x03 0x0b 0x01 0xc6 0x03 0x0a 0x01 0xc6 0x03 0x09 0x01 0xc6 0x03 0x08 0x01 0xc6 0x03 0x07 0x01 0xc6 0x03 0x06 0x01 0xc6 0x03 0x05 0x01 0xc7 0x03 0x04 0x01 0xc7>;
				phandle = <0x14f>;
			};
		};

		i2c0 {

			i2c0-xfer {
				rockchip,pins = <0x01 0x0f 0x02 0xc6 0x01 0x10 0x02 0xc6>;
				phandle = <0x8b>;
			};
		};

		i2c1 {

			i2c1-xfer {
				rockchip,pins = <0x04 0x02 0x01 0xc6 0x04 0x01 0x01 0xc6>;
				phandle = <0x37>;
			};
		};

		i2c2 {

			i2c2-xfer {
				rockchip,pins = <0x02 0x01 0x02 0xc8 0x02 0x00 0x02 0xc8>;
				phandle = <0x3c>;
			};
		};

		i2c3 {

			i2c3-xfer {
				rockchip,pins = <0x04 0x11 0x01 0xc6 0x04 0x10 0x01 0xc6>;
				phandle = <0x43>;
			};
		};

		i2c4 {

			i2c4-xfer {
				rockchip,pins = <0x01 0x0c 0x01 0xc6 0x01 0x0b 0x01 0xc6>;
				phandle = <0x91>;
			};
		};

		i2c5 {

			i2c5-xfer {
				rockchip,pins = <0x03 0x0b 0x02 0xc6 0x03 0x0a 0x02 0xc6>;
				phandle = <0x44>;
			};
		};

		i2c6 {

			i2c6-xfer {
				rockchip,pins = <0x02 0x0a 0x02 0xc6 0x02 0x09 0x02 0xc6>;
				phandle = <0x45>;
			};
		};

		i2c7 {

			i2c7-xfer {
				rockchip,pins = <0x02 0x08 0x02 0xc6 0x02 0x07 0x02 0xc6>;
				phandle = <0x46>;
			};
		};

		i2c8 {

			i2c8-xfer {
				rockchip,pins = <0x01 0x15 0x01 0xc6 0x01 0x14 0x01 0xc6>;
				phandle = <0x94>;
			};
		};

		i2s0 {

			i2s0-2ch-bus {
				rockchip,pins = <0x03 0x18 0x01 0xc6 0x03 0x19 0x01 0xc6 0x03 0x1a 0x01 0xc6 0x03 0x1b 0x01 0xc6 0x03 0x1f 0x01 0xc6 0x04 0x00 0x01 0xc6>;
				phandle = <0x150>;
			};

			i2s0-2ch-bus-bclk-off {
				rockchip,pins = <0x03 0x18 0x00 0xc6 0x03 0x19 0x01 0xc6 0x03 0x1a 0x01 0xc6 0x03 0x1b 0x01 0xc6 0x03 0x1f 0x01 0xc6 0x04 0x00 0x01 0xc6>;
				phandle = <0x151>;
			};

			i2s0-8ch-bus {
				rockchip,pins = <0x03 0x18 0x01 0xc6 0x03 0x19 0x01 0xc6 0x03 0x1a 0x01 0xc6 0x03 0x1b 0x01 0xc6 0x03 0x1c 0x01 0xc6 0x03 0x1d 0x01 0xc6 0x03 0x1e 0x01 0xc6 0x03 0x1f 0x01 0xc6 0x04 0x00 0x01 0xc6>;
				phandle = <0xa3>;
			};

			i2s0-8ch-bus-bclk-off {
				rockchip,pins = <0x03 0x18 0x00 0xc6 0x03 0x19 0x01 0xc6 0x03 0x1a 0x01 0xc6 0x03 0x1b 0x01 0xc6 0x03 0x1c 0x01 0xc6 0x03 0x1d 0x01 0xc6 0x03 0x1e 0x01 0xc6 0x03 0x1f 0x01 0xc6 0x04 0x00 0x01 0xc6>;
				phandle = <0xa4>;
			};

			i2s-8ch-mclk-pin {
				rockchip,pins = <0x04 0x00 0x01 0xc6>;
				phandle = <0xa2>;
			};
		};

		i2s1 {

			i2s1-2ch-bus {
				rockchip,pins = <0x04 0x03 0x01 0xc6 0x04 0x04 0x01 0xc6 0x04 0x05 0x01 0xc6 0x04 0x06 0x01 0xc6 0x04 0x07 0x01 0xc6>;
				phandle = <0xa5>;
			};

			i2s1-2ch-bus-bclk-off {
				rockchip,pins = <0x04 0x03 0x00 0xc6 0x04 0x04 0x01 0xc6 0x04 0x05 0x01 0xc6 0x04 0x06 0x01 0xc6 0x04 0x07 0x01 0xc6>;
				phandle = <0x152>;
			};
		};

		sdio0 {

			sdio0-bus1 {
				rockchip,pins = <0x02 0x14 0x01 0xc9>;
				phandle = <0x153>;
			};

			sdio0-bus4 {
				rockchip,pins = <0x02 0x14 0x01 0xc9 0x02 0x15 0x01 0xc9 0x02 0x16 0x01 0xc9 0x02 0x17 0x01 0xc9>;
				phandle = <0x1f>;
			};

			sdio0-cmd {
				rockchip,pins = <0x02 0x18 0x01 0xc9>;
				phandle = <0x20>;
			};

			sdio0-clk {
				rockchip,pins = <0x02 0x19 0x01 0xc6>;
				phandle = <0x21>;
			};

			sdio0-cd {
				rockchip,pins = <0x02 0x1a 0x01 0xc9>;
				phandle = <0x154>;
			};

			sdio0-pwr {
				rockchip,pins = <0x02 0x1b 0x01 0xc9>;
				phandle = <0x155>;
			};

			sdio0-bkpwr {
				rockchip,pins = <0x02 0x1c 0x01 0xc9>;
				phandle = <0x156>;
			};

			sdio0-wp {
				rockchip,pins = <0x00 0x03 0x01 0xc9>;
				phandle = <0x157>;
			};

			sdio0-int {
				rockchip,pins = <0x00 0x04 0x01 0xc9>;
				phandle = <0x158>;
			};
		};

		sdmmc {

			sdmmc-bus1 {
				rockchip,pins = <0x04 0x08 0x01 0xc9>;
				phandle = <0x159>;
			};

			sdmmc-bus4 {
				rockchip,pins = <0x04 0x08 0x01 0xc9 0x04 0x09 0x01 0xc9 0x04 0x0a 0x01 0xc9 0x04 0x0b 0x01 0xc9>;
				phandle = <0x26>;
			};

			sdmmc-clk {
				rockchip,pins = <0x04 0x0c 0x01 0xc6>;
				phandle = <0x23>;
			};

			sdmmc-cmd {
				rockchip,pins = <0x04 0x0d 0x01 0xc9>;
				phandle = <0x24>;
			};

			sdmmc-cd {
				rockchip,pins = <0x00 0x07 0x01 0xc9>;
				phandle = <0x25>;
			};

			sdmmc-wp {
				rockchip,pins = <0x00 0x08 0x01 0xc9>;
				phandle = <0x15a>;
			};
		};

		suspend {

			ap-pwroff {
				rockchip,pins = <0x01 0x05 0x01 0xc6>;
				phandle = <0x15b>;
			};

			ddrio-pwroff {
				rockchip,pins = <0x00 0x01 0x01 0xc6>;
				phandle = <0x15c>;
			};
		};

		spdif {

			spdif-bus {
				rockchip,pins = <0x04 0x15 0x01 0xc6>;
				phandle = <0xa1>;
			};

			spdif-bus-1 {
				rockchip,pins = <0x03 0x10 0x03 0xc6>;
				phandle = <0x15d>;
			};
		};

		spi0 {

			spi0-clk {
				rockchip,pins = <0x03 0x06 0x02 0xc9>;
				phandle = <0x53>;
			};

			spi0-cs0 {
				rockchip,pins = <0x03 0x07 0x02 0xc9>;
				phandle = <0x56>;
			};

			spi0-cs1 {
				rockchip,pins = <0x03 0x08 0x02 0xc9>;
				phandle = <0x15e>;
			};

			spi0-tx {
				rockchip,pins = <0x03 0x05 0x02 0xc9>;
				phandle = <0x54>;
			};

			spi0-rx {
				rockchip,pins = <0x03 0x04 0x02 0xc9>;
				phandle = <0x55>;
			};
		};

		spi1 {

			spi1-clk {
				rockchip,pins = <0x01 0x09 0x02 0xc9>;
				phandle = <0x57>;
			};

			spi1-cs0 {
				rockchip,pins = <0x01 0x0a 0x02 0xc9>;
				phandle = <0x5a>;
			};

			spi1-rx {
				rockchip,pins = <0x01 0x07 0x02 0xc9>;
				phandle = <0x59>;
			};

			spi1-tx {
				rockchip,pins = <0x01 0x08 0x02 0xc9>;
				phandle = <0x58>;
			};
		};

		spi2 {

			spi2-clk {
				rockchip,pins = <0x02 0x0b 0x01 0xc9>;
				phandle = <0x5b>;
			};

			spi2-cs0 {
				rockchip,pins = <0x02 0x0c 0x01 0xc9>;
				phandle = <0x5e>;
			};

			spi2-rx {
				rockchip,pins = <0x02 0x09 0x01 0xc9>;
				phandle = <0x5d>;
			};

			spi2-tx {
				rockchip,pins = <0x02 0x0a 0x01 0xc9>;
				phandle = <0x5c>;
			};
		};

		spi3 {

			spi3-clk {
				rockchip,pins = <0x01 0x11 0x01 0xc9>;
				phandle = <0x86>;
			};

			spi3-cs0 {
				rockchip,pins = <0x01 0x12 0x01 0xc9>;
				phandle = <0x89>;
			};

			spi3-rx {
				rockchip,pins = <0x01 0x0f 0x01 0xc9>;
				phandle = <0x88>;
			};

			spi3-tx {
				rockchip,pins = <0x01 0x10 0x01 0xc9>;
				phandle = <0x87>;
			};
		};

		spi4 {

			spi4-clk {
				rockchip,pins = <0x03 0x02 0x02 0xc9>;
				phandle = <0x5f>;
			};

			spi4-cs0 {
				rockchip,pins = <0x03 0x03 0x02 0xc9>;
				phandle = <0x62>;
			};

			spi4-rx {
				rockchip,pins = <0x03 0x00 0x02 0xc9>;
				phandle = <0x61>;
			};

			spi4-tx {
				rockchip,pins = <0x03 0x01 0x02 0xc9>;
				phandle = <0x60>;
			};
		};

		spi5 {

			spi5-clk {
				rockchip,pins = <0x02 0x16 0x02 0xc9>;
				phandle = <0x64>;
			};

			spi5-cs0 {
				rockchip,pins = <0x02 0x17 0x02 0xc9>;
				phandle = <0x67>;
			};

			spi5-rx {
				rockchip,pins = <0x02 0x14 0x02 0xc9>;
				phandle = <0x66>;
			};

			spi5-tx {
				rockchip,pins = <0x02 0x15 0x02 0xc9>;
				phandle = <0x65>;
			};
		};

		testclk {

			test-clkout0 {
				rockchip,pins = <0x00 0x00 0x01 0xc6>;
				phandle = <0x15f>;
			};

			test-clkout1 {
				rockchip,pins = <0x02 0x19 0x02 0xc6>;
				phandle = <0x160>;
			};

			test-clkout2 {
				rockchip,pins = <0x00 0x08 0x03 0xc6>;
				phandle = <0x161>;
			};
		};

		tsadc {

			otp-pin {
				rockchip,pins = <0x01 0x06 0x00 0xc6>;
				phandle = <0x6d>;
			};

			otp-out {
				rockchip,pins = <0x01 0x06 0x01 0xc6>;
				phandle = <0x6e>;
			};

			otp-gpio {
				rockchip,pins = <0x01 0x06 0x00 0xc6>;
				phandle = <0x162>;
			};
		};

		uart0 {

			uart0-xfer {
				rockchip,pins = <0x02 0x10 0x01 0xc9 0x02 0x11 0x01 0xc6>;
				phandle = <0x47>;
			};

			uart0-cts {
				rockchip,pins = <0x02 0x12 0x01 0xc6>;
				phandle = <0x48>;
			};

			uart0-rts {
				rockchip,pins = <0x02 0x13 0x01 0xc6>;
				phandle = <0x49>;
			};
		};

		uart1 {

			uart1-xfer {
				rockchip,pins = <0x03 0x0c 0x02 0xc9 0x03 0x0d 0x02 0xc6>;
				phandle = <0x4f>;
			};
		};

		uart2a {

			uart2a-xfer {
				rockchip,pins = <0x04 0x08 0x02 0xc9 0x04 0x09 0x02 0xc6>;
				phandle = <0x163>;
			};
		};

		uart2b {

			uart2b-xfer {
				rockchip,pins = <0x04 0x10 0x02 0xc9 0x04 0x11 0x02 0xc6>;
				phandle = <0x164>;
			};
		};

		uart2c {

			uart2c-xfer {
				rockchip,pins = <0x04 0x13 0x01 0xc9 0x04 0x14 0x01 0xc6>;
				phandle = <0x50>;
			};
		};

		uart3 {

			uart3-xfer {
				rockchip,pins = <0x03 0x0e 0x02 0xc9 0x03 0x0f 0x02 0xc6>;
				phandle = <0x51>;
			};

			uart3-cts {
				rockchip,pins = <0x03 0x10 0x02 0xc6>;
				phandle = <0x165>;
			};

			uart3-rts {
				rockchip,pins = <0x03 0x11 0x02 0xc6>;
				phandle = <0x166>;
			};
		};

		uart4 {

			uart4-xfer {
				rockchip,pins = <0x01 0x07 0x01 0xc9 0x01 0x08 0x01 0xc6>;
				phandle = <0x8a>;
			};
		};

		uarthdcp {

			uarthdcp-xfer {
				rockchip,pins = <0x04 0x15 0x02 0xc9 0x04 0x16 0x02 0xc6>;
				phandle = <0x167>;
			};
		};

		pwm0 {

			pwm0-pin {
				rockchip,pins = <0x04 0x12 0x01 0xc6>;
				phandle = <0x95>;
			};

			pwm0-pin-pull-down {
				rockchip,pins = <0x04 0x12 0x01 0xca>;
				phandle = <0x168>;
			};

			vop0-pwm-pin {
				rockchip,pins = <0x04 0x12 0x02 0xc6>;
				phandle = <0x169>;
			};

			vop1-pwm-pin {
				rockchip,pins = <0x04 0x12 0x03 0xc6>;
				phandle = <0x16a>;
			};
		};

		pwm1 {

			pwm1-pin {
				rockchip,pins = <0x04 0x16 0x01 0xc6>;
				phandle = <0x96>;
			};

			pwm1-pin-pull-down {
				rockchip,pins = <0x04 0x16 0x01 0xca>;
				phandle = <0x16b>;
			};
		};

		pwm2 {

			pwm2-pin {
				rockchip,pins = <0x01 0x13 0x01 0xc6>;
				phandle = <0x97>;
			};

			pwm2-pin-pull-down {
				rockchip,pins = <0x01 0x13 0x01 0xca>;
				phandle = <0x16c>;
			};
		};

		pwm3a {

			pwm3a-pin {
				rockchip,pins = <0x00 0x06 0x01 0xc6>;
				phandle = <0x98>;
			};
		};

		pwm3b {

			pwm3b-pin {
				rockchip,pins = <0x01 0x0e 0x01 0xc6>;
				phandle = <0x16d>;
			};
		};

		hdmi {

			hdmi-i2c-xfer {
				rockchip,pins = <0x04 0x11 0x03 0xc6 0x04 0x10 0x03 0xc6>;
				phandle = <0x16e>;
			};

			hdmi-cec {
				rockchip,pins = <0x04 0x17 0x01 0xc6>;
				phandle = <0x16f>;
			};
		};

		pcie {

			pci-clkreqn-cpm {
				rockchip,pins = <0x02 0x1a 0x00 0xc6>;
				phandle = <0x170>;
			};

			pci-clkreqnb-cpm {
				rockchip,pins = <0x04 0x18 0x00 0xc6>;
				phandle = <0x171>;
			};
		};

		backlight-enable {

			bl-edp-enable-gpio {
				rockchip,pins = <0x00 0x09 0x00 0xc6>;
				phandle = <0x172>;
			};

			bl-edp-pwr-gpio {
				rockchip,pins = <0x04 0x19 0x00 0xc6>;
			};
		};

		wireless-bluetooth {

			uart0-gpios {
				rockchip,pins = <0x02 0x13 0x00 0xc6>;
				phandle = <0x173>;
			};

			bt-rst {
				rockchip,pins = <0x00 0x09 0x00 0xc6>;
				phandle = <0x174>;
			};
		};

		wifi {

			wifi-host-wake-l {
				rockchip,pins = <0x00 0x03 0x00 0xc6>;
				phandle = <0xd0>;
			};
		};

		es8388_power {

			es8388-en {
				rockchip,pins = <0x02 0x07 0x00 0xc6>;
				phandle = <0xcd>;
			};
		};

		fusb30x {

			fusb0-int {
				rockchip,pins = <0x02 0x05 0x00 0xc9>;
				phandle = <0x3d>;
			};
		};

		4g-moudle {

			lte-vbat {
				rockchip,pins = <0x01 0x03 0x00 0xc6>;
				phandle = <0xd6>;
			};

			lte-reset {
				rockchip,pins = <0x01 0x02 0x00 0xc6>;
				phandle = <0xd7>;
			};
		};

		mma8452 {

			mma8452-irq-gpio {
				rockchip,pins = <0x04 0x1d 0x00 0xc6>;
				phandle = <0x93>;
			};
		};

		pmic {

			pmic-int-l {
				rockchip,pins = <0x01 0x15 0x00 0xc9>;
				phandle = <0x8e>;
			};

			vsel1-gpio {
				rockchip,pins = <0x01 0x11 0x00 0xca>;
				phandle = <0x8c>;
			};

			vsel2-gpio {
				rockchip,pins = <0x01 0x0e 0x00 0xca>;
				phandle = <0x8d>;
			};
		};

		buttons {

			pwr-btn {
				rockchip,pins = <0x00 0x05 0x00 0xc9>;
				phandle = <0xda>;
			};
		};

		sd {

			sdmmc0-pwr-h {
				rockchip,pins = <0x00 0x01 0x00 0xc6>;
				phandle = <0xce>;
			};
		};

		sdio-pwrseq {

			wifi-enable-h {
				rockchip,pins = <0x00 0x0a 0x00 0xc6>;
				phandle = <0xcf>;
			};
		};

		bluetooth {

			bt-enable-h {
				rockchip,pins = <0x00 0x09 0x00 0xc6>;
				phandle = <0x4d>;
			};

			bt-host-wake-l {
				rockchip,pins = <0x00 0x04 0x00 0xc6>;
				phandle = <0x4b>;
			};

			bt-wake-l {
				rockchip,pins = <0x02 0x1b 0x00 0xc6>;
				phandle = <0x4c>;
			};
		};

		usb-typec {

			vcc-vbus-typec0-en {
				rockchip,pins = <0x01 0x0d 0x00 0xc6>;
				phandle = <0xd5>;
			};
		};

		usb-power {

			usb20-host0-pwr-gpio {
				rockchip,pins = <0x01 0x00 0x00 0xc6>;
				phandle = <0xd1>;
			};

			usb20-host1-pwr-gpio {
				rockchip,pins = <0x01 0x01 0x00 0xc6>;
				phandle = <0xd2>;
			};

			usb20-host1-rst-gpio {
				rockchip,pins = <0x04 0x07 0x00 0xc6>;
				phandle = <0xd3>;
			};

			usb30-host2-pwr-gpio {
				rockchip,pins = <0x01 0x16 0x00 0xc6>;
				phandle = <0xd4>;
			};
		};

		es8388 {

			amp-gain {
				rockchip,pins = <0x01 0x12 0x00 0xc6>;
				phandle = <0x39>;
			};

			spk-ctl {
				rockchip,pins = <0x01 0x18 0x00 0xc6>;
				phandle = <0x3a>;
			};
		};
	};

	opp-table-0 {
		compatible = "operating-points-v2";
		opp-shared;
		phandle = <0x0b>;

		opp00 {
			opp-hz = <0x00 0x18519600>;
			opp-microvolt = <0xc96a8 0xc96a8 0x1312d0>;
			clock-latency-ns = <0x9c40>;
		};

		opp01 {
			opp-hz = <0x00 0x23c34600>;
			opp-microvolt = <0xc96a8 0xc96a8 0x1312d0>;
		};

		opp02 {
			opp-hz = <0x00 0x30a32c00>;
			opp-microvolt = <0xcf850 0xcf850 0x1312d0>;
		};

		opp03 {
			opp-hz = <0x00 0x3c14dc00>;
			opp-microvolt = <0xe1d48 0xe1d48 0x1312d0>;
		};

		opp04 {
			opp-hz = <0x00 0x47868c00>;
			opp-microvolt = <0xf4240 0xf4240 0x1312d0>;
		};

		opp05 {
			opp-hz = <0x00 0x54667200>;
			opp-microvolt = <0x112a88 0x112a88 0x1312d0>;
		};
	};

	opp-table-1 {
		compatible = "operating-points-v2";
		opp-shared;
		phandle = <0x0d>;

		opp00 {
			opp-hz = <0x00 0x18519600>;
			opp-microvolt = <0xc96a8 0xc96a8 0x1312d0>;
			clock-latency-ns = <0x9c40>;
		};

		opp01 {
			opp-hz = <0x00 0x23c34600>;
			opp-microvolt = <0xc96a8 0xc96a8 0x1312d0>;
		};

		opp02 {
			opp-hz = <0x00 0x30a32c00>;
			opp-microvolt = <0xc96a8 0xc96a8 0x1312d0>;
		};

		opp03 {
			opp-hz = <0x00 0x3c14dc00>;
			opp-microvolt = <0xd59f8 0xd59f8 0x1312d0>;
		};

		opp04 {
			opp-hz = <0x00 0x47868c00>;
			opp-microvolt = <0xe7ef0 0xe7ef0 0x1312d0>;
		};

		opp05 {
			opp-hz = <0x00 0x54667200>;
			opp-microvolt = <0xfa3e8 0xfa3e8 0x1312d0>;
		};

		opp06 {
			opp-hz = <0x00 0x5fd82200>;
			opp-microvolt = <0x10c8e0 0x10c8e0 0x1312d0>;
		};

		opp07 {
			opp-hz = <0x00 0x6b49d200>;
			opp-microvolt = <0x124f80 0x124f80 0x1312d0>;
		};
	};

	opp-table-2 {
		compatible = "operating-points-v2";
		phandle = <0xc4>;

		opp00 {
			opp-hz = <0x00 0xbebc200>;
			opp-microvolt = <0xc96a8 0xc96a8 0x118c30>;
		};

		opp01 {
			opp-hz = <0x00 0x11b3dc40>;
			opp-microvolt = <0xc96a8 0xc96a8 0x118c30>;
		};

		opp02 {
			opp-hz = <0x00 0x17d78400>;
			opp-microvolt = <0xc96a8 0xc96a8 0x118c30>;
		};

		opp03 {
			opp-hz = <0x00 0x1dcd6500>;
			opp-microvolt = <0xd59f8 0xd59f8 0x118c30>;
		};

		opp04 {
			opp-hz = <0x00 0x23c34600>;
			opp-microvolt = <0xe1d48 0xe1d48 0x118c30>;
		};

		opp05 {
			opp-hz = <0x00 0x2faf0800>;
			opp-microvolt = <0x10c8e0 0x10c8e0 0x118c30>;
		};
	};

	external-gmac-clock {
		compatible = "fixed-clock";
		clock-frequency = <0x7735940>;
		clock-output-names = "clkin_gmac";
		#clock-cells = <0x00>;
		phandle = <0x1c>;
	};

	dc-12v {
		compatible = "regulator-fixed";
		regulator-name = "dc_12v";
		regulator-always-on;
		regulator-boot-on;
		regulator-min-microvolt = <0xb71b00>;
		regulator-max-microvolt = <0xb71b00>;
		phandle = <0xcb>;
	};

	vcc1v8-s3 {
		compatible = "regulator-fixed";
		regulator-name = "vcc1v8_s3";
		regulator-always-on;
		regulator-boot-on;
		regulator-min-microvolt = <0x1b7740>;
		regulator-max-microvolt = <0x1b7740>;
		vin-supply = <0x36>;
		phandle = <0x175>;
	};

	vcc-sys {
		compatible = "regulator-fixed";
		regulator-name = "vcc_sys";
		regulator-always-on;
		regulator-boot-on;
		regulator-min-microvolt = <0x4c4b40>;
		regulator-max-microvolt = <0x4c4b40>;
		vin-supply = <0xcb>;
		phandle = <0x8f>;
	};

	vcc3v3-sys {
		compatible = "regulator-fixed";
		regulator-name = "vcc3v3_sys";
		regulator-always-on;
		regulator-boot-on;
		regulator-min-microvolt = <0x325aa0>;
		regulator-max-microvolt = <0x325aa0>;
		vin-supply = <0x8f>;
		phandle = <0x90>;
	};

	vcc5v0-host-regulator {
		compatible = "regulator-fixed";
		regulator-name = "vcc5v0_host";
		regulator-always-on;
		vin-supply = <0x8f>;
		phandle = <0x9c>;
	};

	vcc5v0-sys {
		compatible = "regulator-fixed";
		regulator-name = "vcc5v0_sys";
		regulator-always-on;
		regulator-boot-on;
		regulator-min-microvolt = <0x4c4b40>;
		regulator-max-microvolt = <0x4c4b40>;
		phandle = <0x4e>;
	};

	vdd-log {
		compatible = "pwm-regulator";
		pwms = <0xcc 0x00 0x61a8 0x01>;
		rockchip,pwm_id = <0x02>;
		rockchip,pwm_voltage = <0xf4240>;
		regulator-name = "vdd_log";
		regulator-always-on;
		regulator-boot-on;
		regulator-min-microvolt = "\0\f5";
		regulator-max-microvolt = <0x155cc0>;
		vin-supply = <0x8f>;
		phandle = <0x176>;
	};

	vcc-es8388-regulator {
		compatible = "regulator-fixed";
		enable-active-high;
		gpio = <0x3e 0x07 0x00>;
		pinctrl-names = "default";
		pinctrl-0 = <0xcd>;
		regulator-name = "vcc_es8388";
		regulator-boot-on;
		regulator-always-on;
		vin-supply = <0x8f>;
		phandle = <0x3b>;
	};

	vcc-sd {
		compatible = "regulator-fixed";
		enable-active-high;
		gpio = <0x22 0x01 0x00>;
		pinctrl-names = "default";
		pinctrl-0 = <0xce>;
		regulator-always-on;
		regulator-max-microvolt = <0x2dc6c0>;
		regulator-min-microvolt = <0x2dc6c0>;
		regulator-name = "vcc_sd";
		phandle = <0x28>;
	};

	vcc-lcd {
		compatible = "regulator-fixed";
		regulator-name = "vcc_lcd";
		startup-delay-us = <0x4e20>;
		regulator-min-microvolt = <0x325aa0>;
		regulator-max-microvolt = <0x325aa0>;
		regulator-always-on;
		regulator-boot-on;
		vin-supply = <0x4e>;
		phandle = <0x177>;
	};

	sdio-pwrseq {
		compatible = "mmc-pwrseq-simple";
		clocks = <0x4a 0x01>;
		clock-names = "ext_clock";
		pinctrl-names = "default";
		pinctrl-0 = <0xcf>;
		reset-gpios = <0x22 0x0a 0x01>;
		phandle = <0x1e>;
	};

	wireless-wlan {
		compatible = "wlan-platdata";
		rockchip,grf = <0x19>;
		wifi_chip_type = "rtl8723ds";
		pinctrl-0 = <0xd0>;
		WIFI,host_wake_irq = <0x22 0x03 0x00>;
		status = "okay";
		phandle = <0x178>;
	};

	usb20_host0_pwr {
		status = "okay";
		compatible = "regulator-fixed";
		enable-active-high;
		gpio = <0x38 0x00 0x00>;
		pinctrl-0 = <0xd1>;
		pinctrl-names = "default";
		regulator-name = "usb20_host0_pwr";
		regulator-always-on;
	};

	usb20_host1_pwr {
		status = "okay";
		compatible = "regulator-fixed";
		enable-active-high;
		gpio = <0x38 0x01 0x00>;
		pinctrl-0 = <0xd2>;
		pinctrl-names = "default";
		regulator-name = "usb20_host1_pwr";
		regulator-always-on;
	};

	usb20_host1_rst {
		status = "okay";
		compatible = "regulator-fixed";
		enable-active-high;
		gpio = <0x92 0x07 0x00>;
		pinctrl-0 = <0xd3>;
		pinctrl-names = "default";
		regulator-name = "usb20_host1_rst";
		regulator-always-on;
	};

	usb30_host2_pwr {
		status = "okay";
		compatible = "regulator-fixed";
		enable-active-high;
		gpio = <0x38 0x16 0x00>;
		pinctrl-0 = <0xd4>;
		pinctrl-names = "default";
		regulator-name = "usb30_host2_pwr";
		regulator-always-on;
	};

	vcc-vbus-typec0 {
		compatible = "regulator-fixed";
		enable-active-high;
		gpio = <0x38 0x0d 0x00>;
		pinctrl-names = "default";
		pinctrl-0 = <0xd5>;
		regulator-name = "vcc_vbus_typec0";
		vin-supply = <0x8f>;
		phandle = <0x3f>;
	};

	rk-modem {
		compatible = "4g-modem-platdata";
		pinctrl-names = "default";
		pinctrl-0 = <0xd6 0xd7>;
		4G,vbat-gpio = <0x38 0x03 0x00>;
		4G,reset-gpio = <0x38 0x02 0x00>;
		status = "okay";
		phandle = <0x179>;
	};

	es8388-sound {
		compatible = "simple-audio-card";
		simple-audio-card,format = "i2s";
		simple-audio-card,name = "rockchip,es8388-codec";
		simple-audio-card,mclk-fs = <0x100>;
		simple-audio-card,widgets = "Microphone\0Mic Jack\0Headphone\0Headphone Jack";
		simple-audio-card,routing = "Mic Jack\0MICBIAS1\0IN1P\0Mic Jack\0Headphone Jack\0HPOL\0Headphone Jack\0HPOR";
		status = "okay";
		phandle = <0x17a>;

		simple-audio-card,cpu {
			sound-dai = <0xd8>;
		};

		simple-audio-card,codec {
			sound-dai = <0xd9>;
		};
	};

	gpio-keys {
		compatible = "gpio-keys";
		autorepeat;
		pinctrl-names = "default";
		pinctrl-0 = <0xda>;
		status = "okay";

		power {
			debounce-interval = <0x64>;
			gpios = <0x22 0x05 0x01>;
			label = "GPIO Key Power";
			linux,code = <0x74>;
			wakeup-source;
		};
	};

	backlight {
		status = "okay";
		compatible = "pwm-backlight";
		brightness-levels = <0x2f 0x2f 0x2f 0x2f 0x2f 0x2f 0x30 0x30 0x31 0x31 0x32 0x32 0x33 0x33 0x34 0x34 0x35 0x35 0x36 0x36 0x37 0x37 0x38 0x38 0x39 0x39 0x3a 0x3a 0x3b 0x3b 0x3c 0x3c 0x3d 0x3d 0x3e 0x3e 0x3f 0x3f 0x40 0x40 0x41 0x41 0x42 0x42 0x43 0x43 0x44 0x44 0x45 0x45 0x46 0x46 0x47 0x47 0x48 0x48 0x49 0x49 0x4a 0x4a 0x4b 0x4b 0x4c 0x4c 0x4d 0x4d 0x4e 0x4e 0x4f 0x4f 0x50 0x50 0x51 0x51 0x52 0x52 0x53 0x53 0x54 0x54 0x55 0x55 0x56 0x56 0x57 0x57 0x58 0x58 0x59 0x59 0x5a 0x5b 0x5c 0x5d 0x5e 0x5f 0x60 0x61 0x62 0x63 0x64 0x65 0x66 0x67 0x68 0x69 0x6a 0x6b 0x6c 0x6d 0x6e 0x6f 0x70 0x71 0x72 0x73 0x74 0x75 0x76 0x77 0x78 0x79 0x7a 0x7b 0x7c 0x7d 0x7e 0x7f 0x80 0x81 0x82 0x83 0x84 0x85 0x86 0x87 0x88 0x89 0x8a 0x8b 0x8c 0x8d 0x8e 0x8f 0x90 0x91 0x92 0x93 0x94 0x95 0x96 0x97 0x98 0x99 0x9a 0x9b 0x9c 0x9d 0x9e 0x9f 0xa0 0xa1 0xa2 0xa3 0xa4 0xa5 0xa6 0xa7 0xa8 0xa9 0xaa 0xab 0xac 0xad 0xae 0xaf 0xb0 0xb1 0xb2 0xb3 0xb4 0xb5 0xb6 0xb7 0xb8 0xb9 0xba 0xbb 0xbc 0xbd 0xbe 0xbf 0xc0 0xc1 0xc2 0xc3 0xc4 0xc5 0xc6 0xc7 0xc8 0xc9 0xca 0xcb 0xcc 0xcd 0xce 0xcf 0xd0 0xd1 0xd2 0xd3 0xd4 0xd5 0xd6 0xd7 0xd8 0xd9 0xda 0xdb 0xdc 0xdd 0xde 0xdf 0xe0 0xe1 0xe2 0xe3 0xe4 0xe5 0xe6 0xe7 0xe8 0xe9 0xea 0xeb 0xec 0xed 0xee 0xef 0xf0 0xf1 0xf2 0xf3 0xf4 0xf5 0xf6 0xf7 0xf8 0xf9 0xfa 0xfb 0xfc 0xfd 0xfe 0xff>;
		default-brightness-level = <0xc8>;
		enable-gpios = <0x92 0x19 0x00>;
		pwms = <0xdb 0x00 0x4c4b40 0x01>;
	};

};
